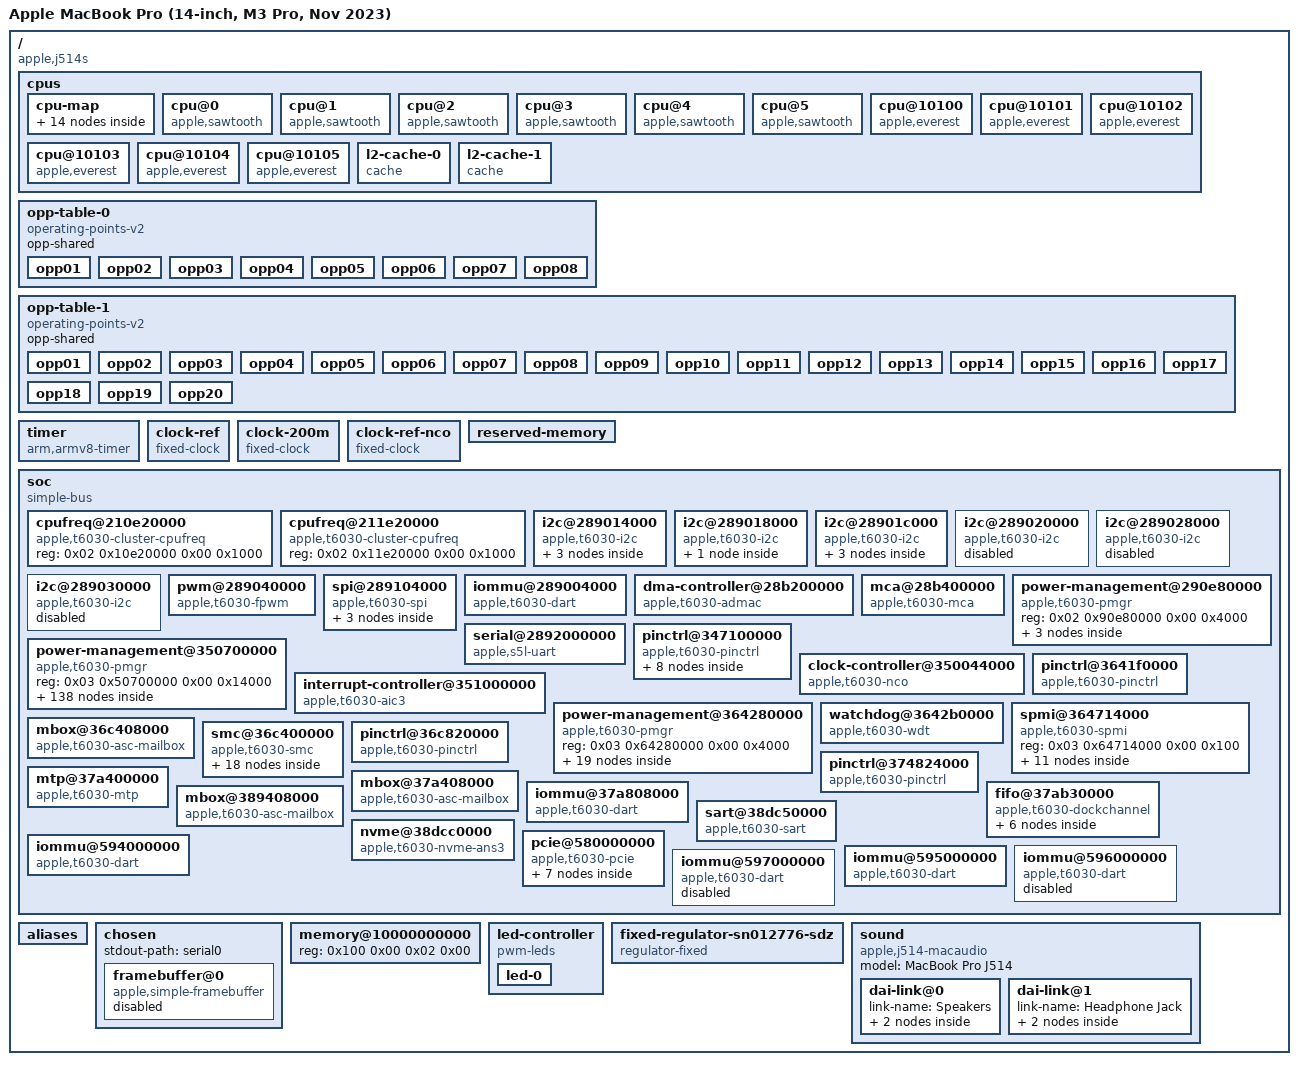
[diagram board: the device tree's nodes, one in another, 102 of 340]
/dts-v1/;

/ {
	#address-cells = <0x02>;
	#size-cells = <0x02>;
	chassis-type = "laptop";
	compatible = "apple,j514s", "apple,t6030", "apple,arm-platform";
	model = "Apple MacBook Pro (14-inch, M3 Pro, Nov 2023)";

	cpus {
		#address-cells = <0x02>;
		#size-cells = <0x00>;

		cpu-map {

			cluster0 {

				core0 {
					cpu = <0x01>;
				};

				core1 {
					cpu = <0x02>;
				};

				core2 {
					cpu = <0x03>;
				};

				core3 {
					cpu = <0x04>;
				};

				core4 {
					cpu = <0x05>;
				};

				core5 {
					cpu = <0x06>;
				};
			};

			cluster1 {

				core0 {
					cpu = <0x07>;
				};

				core1 {
					cpu = <0x08>;
				};

				core2 {
					cpu = <0x09>;
				};

				core3 {
					cpu = <0x0a>;
				};

				core4 {
					cpu = <0x0b>;
				};

				core5 {
					cpu = <0x0c>;
				};
			};
		};

		cpu@0 {
			compatible = "apple,sawtooth";
			device_type = "cpu";
			reg = <0x00 0x00>;
			enable-method = "spin-table";
			cpu-release-addr = <0x00 0x00>;
			next-level-cache = <0x0d>;
			i-cache-size = <0x20000>;
			d-cache-size = <0x10000>;
			operating-points-v2 = <0x0e>;
			capacity-dmips-mhz = <0x353>;
			performance-domains = <0x0f>;
			phandle = <0x01>;
		};

		cpu@1 {
			compatible = "apple,sawtooth";
			device_type = "cpu";
			reg = <0x00 0x01>;
			enable-method = "spin-table";
			cpu-release-addr = <0x00 0x00>;
			next-level-cache = <0x0d>;
			i-cache-size = <0x20000>;
			d-cache-size = <0x10000>;
			operating-points-v2 = <0x0e>;
			capacity-dmips-mhz = <0x353>;
			performance-domains = <0x0f>;
			phandle = <0x02>;
		};

		cpu@2 {
			compatible = "apple,sawtooth";
			device_type = "cpu";
			reg = <0x00 0x02>;
			enable-method = "spin-table";
			cpu-release-addr = <0x00 0x00>;
			next-level-cache = <0x0d>;
			i-cache-size = <0x20000>;
			d-cache-size = <0x10000>;
			operating-points-v2 = <0x0e>;
			capacity-dmips-mhz = <0x353>;
			performance-domains = <0x0f>;
			phandle = <0x03>;
		};

		cpu@3 {
			compatible = "apple,sawtooth";
			device_type = "cpu";
			reg = <0x00 0x03>;
			enable-method = "spin-table";
			cpu-release-addr = <0x00 0x00>;
			next-level-cache = <0x0d>;
			i-cache-size = <0x20000>;
			d-cache-size = <0x10000>;
			operating-points-v2 = <0x0e>;
			capacity-dmips-mhz = <0x353>;
			performance-domains = <0x0f>;
			phandle = <0x04>;
		};

		cpu@4 {
			compatible = "apple,sawtooth";
			device_type = "cpu";
			reg = <0x00 0x04>;
			enable-method = "spin-table";
			cpu-release-addr = <0x00 0x00>;
			next-level-cache = <0x0d>;
			i-cache-size = <0x20000>;
			d-cache-size = <0x10000>;
			operating-points-v2 = <0x0e>;
			capacity-dmips-mhz = <0x353>;
			performance-domains = <0x0f>;
			phandle = <0x05>;
		};

		cpu@5 {
			compatible = "apple,sawtooth";
			device_type = "cpu";
			reg = <0x00 0x05>;
			enable-method = "spin-table";
			cpu-release-addr = <0x00 0x00>;
			next-level-cache = <0x0d>;
			i-cache-size = <0x20000>;
			d-cache-size = <0x10000>;
			operating-points-v2 = <0x0e>;
			capacity-dmips-mhz = <0x353>;
			performance-domains = <0x0f>;
			phandle = <0x06>;
		};

		cpu@10100 {
			compatible = "apple,everest";
			device_type = "cpu";
			reg = <0x00 0x10100>;
			enable-method = "spin-table";
			cpu-release-addr = <0x00 0x00>;
			next-level-cache = <0x10>;
			i-cache-size = <0x30000>;
			d-cache-size = <0x20000>;
			operating-points-v2 = <0x11>;
			capacity-dmips-mhz = <0x400>;
			performance-domains = <0x12>;
			phandle = <0x07>;
		};

		cpu@10101 {
			compatible = "apple,everest";
			device_type = "cpu";
			reg = <0x00 0x10101>;
			enable-method = "spin-table";
			cpu-release-addr = <0x00 0x00>;
			next-level-cache = <0x10>;
			i-cache-size = <0x30000>;
			d-cache-size = <0x20000>;
			operating-points-v2 = <0x11>;
			capacity-dmips-mhz = <0x400>;
			performance-domains = <0x12>;
			phandle = <0x08>;
		};

		cpu@10102 {
			compatible = "apple,everest";
			device_type = "cpu";
			reg = <0x00 0x10102>;
			enable-method = "spin-table";
			cpu-release-addr = <0x00 0x00>;
			next-level-cache = <0x10>;
			i-cache-size = <0x30000>;
			d-cache-size = <0x20000>;
			operating-points-v2 = <0x11>;
			capacity-dmips-mhz = <0x400>;
			performance-domains = <0x12>;
			phandle = <0x09>;
		};

		cpu@10103 {
			compatible = "apple,everest";
			device_type = "cpu";
			reg = <0x00 0x10103>;
			enable-method = "spin-table";
			cpu-release-addr = <0x00 0x00>;
			next-level-cache = <0x10>;
			i-cache-size = <0x30000>;
			d-cache-size = <0x20000>;
			operating-points-v2 = <0x11>;
			capacity-dmips-mhz = <0x400>;
			performance-domains = <0x12>;
			phandle = <0x0a>;
		};

		cpu@10104 {
			compatible = "apple,everest";
			device_type = "cpu";
			reg = <0x00 0x10104>;
			enable-method = "spin-table";
			cpu-release-addr = <0x00 0x00>;
			next-level-cache = <0x10>;
			i-cache-size = <0x30000>;
			d-cache-size = <0x20000>;
			operating-points-v2 = <0x11>;
			capacity-dmips-mhz = <0x400>;
			performance-domains = <0x12>;
			phandle = <0x0b>;
		};

		cpu@10105 {
			compatible = "apple,everest";
			device_type = "cpu";
			reg = <0x00 0x10105>;
			enable-method = "spin-table";
			cpu-release-addr = <0x00 0x00>;
			next-level-cache = <0x10>;
			i-cache-size = <0x30000>;
			d-cache-size = <0x20000>;
			operating-points-v2 = <0x11>;
			capacity-dmips-mhz = <0x400>;
			performance-domains = <0x12>;
			phandle = <0x0c>;
		};

		l2-cache-0 {
			compatible = "cache";
			cache-level = <0x02>;
			cache-unified;
			cache-size = <0x400000>;
			phandle = <0x0d>;
		};

		l2-cache-1 {
			compatible = "cache";
			cache-level = <0x02>;
			cache-unified;
			cache-size = <0x1000000>;
			phandle = <0x10>;
		};
	};

	opp-table-0 {
		compatible = "operating-points-v2";
		opp-shared;
		phandle = <0x0e>;

		opp01 {
			opp-hz = <0x00 0x2c588a00>;
			opp-level = <0x01>;
			clock-latency-ns = <0x1e14>;
		};

		opp02 {
			opp-hz = <0x00 0x3e3a2d00>;
			opp-level = <0x02>;
			clock-latency-ns = <0x52d0>;
		};

		opp03 {
			opp-hz = <0x00 0x57f9f900>;
			opp-level = <0x03>;
			clock-latency-ns = <0x6720>;
		};

		opp04 {
			opp-hz = <0x00 0x77729d00>;
			opp-level = <0x04>;
			clock-latency-ns = <0x9e34>;
		};

		opp05 {
			opp-hz = <0x00 0x872eef00>;
			opp-level = <0x05>;
			clock-latency-ns = <0xad70>;
		};

		opp06 {
			opp-hz = <0x00 0x91e98400>;
			opp-level = <0x06>;
			clock-latency-ns = <0xb860>;
		};

		opp07 {
			opp-hz = <0x00 0x9d5b3400>;
			opp-level = <0x07>;
			clock-latency-ns = <0xcb20>;
		};

		opp08 {
			opp-hz = <0x00 0xa3cb2700>;
			opp-level = <0x08>;
			clock-latency-ns = <0xcb20>;
		};
	};

	opp-table-1 {
		compatible = "operating-points-v2";
		opp-shared;
		phandle = <0x11>;

		opp01 {
			opp-hz = <0x00 0x297c1e00>;
			opp-level = <0x01>;
			clock-latency-ns = <0x2198>;
		};

		opp02 {
			opp-hz = <0x00 0x41169900>;
			opp-level = <0x02>;
			clock-latency-ns = <0x490c>;
		};

		opp03 {
			opp-hz = <0x00 0x50d2eb00>;
			opp-level = <0x03>;
			clock-latency-ns = <0x50dc>;
		};

		opp04 {
			opp-hz = <0x00 0x5f210700>;
			opp-level = <0x04>;
			clock-latency-ns = <0x60e0>;
		};

		opp05 {
			opp-hz = <0x00 0x704b8f00>;
			opp-level = <0x05>;
			clock-latency-ns = <0x77ec>;
		};

		opp06 {
			opp-hz = <0x00 0x81761700>;
			opp-level = <0x06>;
			clock-latency-ns = <0x8660>;
		};

		opp07 {
			opp-hz = <0x00 0x907b4e00>;
			opp-level = <0x07>;
			clock-latency-ns = <0x9ab0>;
		};

		opp08 {
			opp-hz = <0x00 0x9becfe00>;
			opp-level = <0x08>;
			clock-latency-ns = <0x9c40>;
		};

		opp09 {
			opp-hz = <0x00 0xa75eae00>;
			opp-level = <0x09>;
			clock-latency-ns = <0xa348>;
		};

		opp10 {
			opp-hz = <0x00 0xb2194300>;
			opp-level = <0x0a>;
			clock-latency-ns = <0xb0f4>;
		};

		opp11 {
			opp-hz = <0x00 0xbb65a200>;
			opp-level = <0x0b>;
			clock-latency-ns = <0xb66c>;
		};

		opp12 {
			opp-hz = <0x00 0xc3fae600>;
			opp-level = <0x0c>;
			clock-latency-ns = <0xc030>;
		};

		opp13 {
			opp-hz = <0x00 0xcbd90f00>;
			opp-level = <0x0d>;
			clock-latency-ns = <0xd28c>;
		};

		opp14 {
			opp-hz = <0x00 0xd5256e00>;
			opp-level = <0x0e>;
			clock-latency-ns = <0xd1c4>;
		};

		opp15 {
			opp-hz = <0x00 0xd801da00>;
			opp-level = <0x0f>;
			clock-latency-ns = <0xd2f0>;
		};

		opp16 {
			opp-hz = <0x00 0xdd039700>;
			opp-level = <0x10>;
			clock-latency-ns = <0xd2f0>;
		};

		opp17 {
			opp-hz = <0x00 0xe14e3900>;
			opp-level = <0x11>;
			clock-latency-ns = <0xd354>;
		};

		opp18 {
			opp-hz = <0x00 0xe64ff600>;
			opp-level = <0x12>;
			clock-latency-ns = <0xd41c>;
		};

		opp19 {
			opp-hz = <0x00 0xec08ce00>;
			opp-level = <0x13>;
			clock-latency-ns = <0xe420>;
		};

		opp20 {
			opp-hz = <0x00 0xf1c1a600>;
			opp-level = <0x14>;
			clock-latency-ns = <0xe54c>;
		};
	};

	timer {
		compatible = "arm,armv8-timer";
		interrupt-parent = <0x13>;
		interrupt-names = "phys", "virt", "hyp-phys", "hyp-virt";
		interrupts = <0x01 0x02 0x04 0x01 0x03 0x04 0x01 0x00 0x04 0x01 0x01 0x04>;
	};

	clock-ref {
		compatible = "fixed-clock";
		#clock-cells = <0x00>;
		clock-frequency = <0x16e3600>;
		clock-output-names = "clkref";
		phandle = <0x14>;
	};

	clock-200m {
		compatible = "fixed-clock";
		#clock-cells = <0x00>;
		clock-frequency = <0xbebc200>;
		clock-output-names = "clk_200m";
		phandle = <0x25>;
	};

	clock-ref-nco {
		compatible = "fixed-clock";
		#clock-cells = <0x00>;
		clock-output-names = "nco_ref";
		clock-frequency = <0x35a4e900>;
		phandle = <0x58>;
	};

	reserved-memory {
		#address-cells = <0x02>;
		#size-cells = <0x02>;
		ranges;
	};

	soc {
		compatible = "simple-bus";
		#address-cells = <0x02>;
		#size-cells = <0x02>;
		ranges;
		nonposted-mmio;
		dma-ranges = <0x00 0x00 0x00 0x00 0xffffffff 0xffffc000>;

		cpufreq@210e20000 {
			compatible = "apple,t6030-cluster-cpufreq", "apple,t8112-cluster-cpufreq";
			reg = <0x02 0x10e20000 0x00 0x1000>;
			#performance-domain-cells = <0x00>;
			phandle = <0x0f>;
		};

		cpufreq@211e20000 {
			compatible = "apple,t6030-cluster-cpufreq", "apple,t8112-cluster-cpufreq";
			reg = <0x02 0x11e20000 0x00 0x1000>;
			#performance-domain-cells = <0x00>;
			phandle = <0x12>;
		};

		i2c@289014000 {
			compatible = "apple,t6030-i2c", "apple,t8103-i2c";
			reg = <0x02 0x89014000 0x00 0x4000>;
			clocks = <0x14>;
			interrupt-parent = <0x13>;
			interrupts = <0x00 0x37a 0x04>;
			pinctrl-0 = <0x15>;
			pinctrl-names = "default";
			#address-cells = <0x01>;
			#size-cells = <0x00>;
			power-domains = <0x16>;
			status = "okay";

			codec@3a {
				compatible = "ti,sn012776", "ti,tas2764";
				reg = <0x3a>;
				SDZ-supply = <0x17>;
				#sound-dai-cells = <0x00>;
				sound-name-prefix = "Left Tweeter";
				interrupts-extended = <0x18 0x1d 0x08>;
				ti,imon-slot-no = <0x08>;
				ti,vmon-slot-no = <0x0a>;
				phandle = <0x7d>;
			};

			codec@38 {
				compatible = "ti,sn012776", "ti,tas2764";
				reg = <0x38>;
				SDZ-supply = <0x17>;
				#sound-dai-cells = <0x00>;
				sound-name-prefix = "Left Woofer 1";
				interrupts-extended = <0x18 0x1d 0x08>;
				ti,imon-slot-no = <0x00>;
				ti,vmon-slot-no = <0x02>;
				ti,sdout-force-zero-mask = <0xf0f0f0>;
				phandle = <0x7c>;
			};

			codec@39 {
				compatible = "ti,sn012776", "ti,tas2764";
				reg = <0x39>;
				SDZ-supply = <0x17>;
				#sound-dai-cells = <0x00>;
				sound-name-prefix = "Left Woofer 2";
				interrupts-extended = <0x18 0x1d 0x08>;
				ti,imon-slot-no = <0x10>;
				ti,vmon-slot-no = <0x12>;
				phandle = <0x7e>;
			};
		};

		i2c@289018000 {
			compatible = "apple,t6030-i2c", "apple,t8103-i2c";
			reg = <0x02 0x89018000 0x00 0x4000>;
			clocks = <0x14>;
			interrupt-parent = <0x13>;
			interrupts = <0x00 0x37b 0x04>;
			pinctrl-0 = <0x19>;
			pinctrl-names = "default";
			#address-cells = <0x01>;
			#size-cells = <0x00>;
			power-domains = <0x1a>;
			status = "okay";

			codec@4b {
				compatible = "cirrus,cs42l84";
				reg = <0x4b>;
				reset-gpios = <0x1b 0x3a 0x00>;
				#sound-dai-cells = <0x00>;
				interrupts-extended = <0x18 0x1e 0x08>;
				sound-name-prefix = "Jack";
				phandle = <0x82>;
			};
		};

		i2c@28901c000 {
			compatible = "apple,t6030-i2c", "apple,t8103-i2c";
			reg = <0x02 0x8901c000 0x00 0x4000>;
			clocks = <0x14>;
			interrupt-parent = <0x13>;
			interrupts = <0x00 0x37c 0x04>;
			pinctrl-0 = <0x1c>;
			pinctrl-names = "default";
			#address-cells = <0x01>;
			#size-cells = <0x00>;
			power-domains = <0x1d>;
			status = "okay";

			codec@3d {
				compatible = "ti,sn012776", "ti,tas2764";
				reg = <0x3d>;
				SDZ-supply = <0x17>;
				#sound-dai-cells = <0x00>;
				sound-name-prefix = "Right Tweeter";
				interrupts-extended = <0x18 0x1d 0x08>;
				ti,imon-slot-no = <0x0c>;
				ti,vmon-slot-no = <0x0e>;
				phandle = <0x80>;
			};

			codec@3b {
				compatible = "ti,sn012776", "ti,tas2764";
				reg = <0x3b>;
				SDZ-supply = <0x17>;
				#sound-dai-cells = <0x00>;
				sound-name-prefix = "Right Woofer 1";
				interrupts-extended = <0x18 0x1d 0x08>;
				ti,imon-slot-no = <0x04>;
				ti,vmon-slot-no = <0x06>;
				ti,sdout-force-zero-mask = <0xf0f0f>;
				phandle = <0x7f>;
			};

			codec@3c {
				compatible = "ti,sn012776", "ti,tas2764";
				reg = <0x3c>;
				SDZ-supply = <0x17>;
				#sound-dai-cells = <0x00>;
				sound-name-prefix = "Right Woofer 2";
				interrupts-extended = <0x18 0x1d 0x08>;
				ti,imon-slot-no = <0x14>;
				ti,vmon-slot-no = <0x16>;
				phandle = <0x81>;
			};
		};

		i2c@289020000 {
			compatible = "apple,t6030-i2c", "apple,t8103-i2c";
			reg = <0x02 0x89020000 0x00 0x4000>;
			clocks = <0x14>;
			interrupt-parent = <0x13>;
			interrupts = <0x00 0x37d 0x04>;
			pinctrl-0 = <0x1e>;
			pinctrl-names = "default";
			#address-cells = <0x01>;
			#size-cells = <0x00>;
			power-domains = <0x1f>;
			status = "disabled";
		};

		i2c@289028000 {
			compatible = "apple,t6030-i2c", "apple,t8103-i2c";
			reg = <0x02 0x89028000 0x00 0x4000>;
			clocks = <0x14>;
			interrupt-parent = <0x13>;
			interrupts = <0x00 0x37f 0x04>;
			pinctrl-0 = <0x20>;
			pinctrl-names = "default";
			#address-cells = <0x01>;
			#size-cells = <0x00>;
			power-domains = <0x21>;
			status = "disabled";
		};

		i2c@289030000 {
			compatible = "apple,t6030-i2c", "apple,t8103-i2c";
			reg = <0x02 0x89030000 0x00 0x4000>;
			clocks = <0x14>;
			interrupt-parent = <0x13>;
			interrupts = <0x00 0x381 0x04>;
			pinctrl-0 = <0x22>;
			pinctrl-names = "default";
			#address-cells = <0x01>;
			#size-cells = <0x00>;
			power-domains = <0x23>;
			status = "disabled";
		};

		pwm@289040000 {
			compatible = "apple,t6030-fpwm", "apple,s5l-fpwm";
			reg = <0x02 0x89040000 0x00 0x4000>;
			power-domains = <0x24>;
			clocks = <0x14>;
			#pwm-cells = <0x02>;
			status = "okay";
			phandle = <0x7a>;
		};

		spi@289104000 {
			compatible = "apple,t6030-spi", "apple,t8103-spi";
			reg = <0x02 0x89104000 0x00 0x4000>;
			interrupt-parent = <0x13>;
			interrupts = <0x00 0x36b 0x04>;
			#address-cells = <0x01>;
			#size-cells = <0x00>;
			clocks = <0x25>;
			pinctrl-0 = <0x26>;
			pinctrl-names = "default";
			power-domains = <0x27>;
			status = "okay";

			flash@0 {
				compatible = "jedec,spi-nor";
				reg = <0x00>;
				spi-max-frequency = <0x17d7840>;

				partitions {
					compatible = "fixed-partitions";
					#address-cells = <0x01>;
					#size-cells = <0x01>;

					partition@700000 {
						label = "nvram";
						reg = <0x00 0x00>;
						status = "disabled";
					};
				};
			};
		};

		iommu@289004000 {
			compatible = "apple,t6030-dart", "apple,t8110-dart";
			reg = <0x02 0x89004000 0x00 0x4000>;
			interrupt-parent = <0x13>;
			interrupts = <0x00 0x385 0x04>;
			#iommu-cells = <0x01>;
			power-domains = <0x28>;
			phandle = <0x29>;
		};

		dma-controller@28b200000 {
			compatible = "apple,t6030-admac", "apple,t8103-admac";
			reg = <0x02 0x8b200000 0x00 0x34000>;
			#dma-cells = <0x01>;
			dma-channels = <0x18>;
			interrupts-extended = <0x00 0x13 0x00 0x378 0x04 0x00 0x00>;
			iommus = <0x29 0x02>;
			power-domains = <0x2a>;
			resets = <0x2b>;
			phandle = <0x2d>;
		};

		mca@28b400000 {
			compatible = "apple,t6030-mca", "apple,t8103-mca";
			reg = <0x02 0x8b400000 0x00 0x10000 0x02 0x8b300000 0x00 0x20000>;
			clocks = <0x2c 0x00 0x2c 0x01 0x2c 0x02 0x2c 0x03>;
			dmas = <0x2d 0x00 0x2d 0x01 0x2d 0x02 0x2d 0x03 0x2d 0x04 0x2d 0x05 0x2d 0x06 0x2d 0x07 0x2d 0x08 0x2d 0x09 0x2d 0x0a 0x2d 0x0b 0x2d 0x0c 0x2d 0x0d 0x2d 0x0e 0x2d 0x0f>;
			dma-names = "tx0a", "rx0a", "tx0b", "rx0b", "tx1a", "rx1a", "tx1b", "rx1b", "tx2a", "rx2a", "tx2b", "rx2b", "tx3a", "rx3a", "tx3b", "rx3b";
			interrupt-parent = <0x13>;
			interrupts = <0x00 0x371 0x04 0x00 0x372 0x04 0x00 0x373 0x04 0x00 0x374 0x04>;
			power-domains = <0x2b 0x2e 0x2f 0x30 0x31>;
			resets = <0x2b>;
			#sound-dai-cells = <0x01>;
			phandle = <0x7b>;
		};

		power-management@290e80000 {
			compatible = "apple,t6030-pmgr", "apple,t8103-pmgr", "syscon", "simple-mfd";
			#address-cells = <0x01>;
			#size-cells = <0x01>;
			reg = <0x02 0x90e80000 0x00 0x4000>;

			power-controller@0 {
				compatible = "apple,t6030-pmgr-pwrstate", "apple,t8103-pmgr-pwrstate";
				reg = <0x00 0x04>;
				#power-domain-cells = <0x00>;
				#reset-cells = <0x00>;
				label = "gpx";
				apple,always-on;
				phandle = <0x32>;
			};

			power-controller@100 {
				compatible = "apple,t6030-pmgr-pwrstate", "apple,t8103-pmgr-pwrstate";
				reg = <0x100 0x04>;
				#power-domain-cells = <0x00>;
				#reset-cells = <0x00>;
				label = "afr";
				apple,always-on;
				phandle = <0x33>;
			};

			power-controller@110 {
				compatible = "apple,t6030-pmgr-pwrstate", "apple,t8103-pmgr-pwrstate";
				reg = <0x110 0x04>;
				#power-domain-cells = <0x00>;
				#reset-cells = <0x00>;
				label = "gfx";
				power-domains = <0x32 0x33>;
			};
		};

		serial@2892000000 {
			compatible = "apple,s5l-uart";
			reg = <0x02 0x89200000 0x00 0x1000>;
			reg-io-width = <0x04>;
			interrupt-parent = <0x13>;
			interrupts = <0x00 0x362 0x04>;
			clocks = <0x14 0x14>;
			clock-names = "uart", "clk_uart_baud0";
			power-domains = <0x34>;
			status = "okay";
		};

		pinctrl@347100000 {
			compatible = "apple,t6030-pinctrl", "apple,t8103-pinctrl";
			reg = <0x03 0x47100000 0x00 0x4000>;
			interrupt-parent = <0x13>;
			interrupts = <0x00 0x111 0x04 0x00 0x112 0x04 0x00 0x113 0x04 0x00 0x114 0x04 0x00 0x115 0x04 0x00 0x116 0x04 0x00 0x117 0x04>;
			power-domains = <0x35>;
			gpio-controller;
			#gpio-cells = <0x02>;
			gpio-ranges = <0x18 0x00 0x00 0xe0>;
			apple,npins = <0xe0>;
			interrupt-controller;
			#interrupt-cells = <0x02>;
			phandle = <0x18>;

			i2c1-pins {
				pinmux = <0x10025 0x10024>;
				phandle = <0x15>;
			};

			i2c2-pins {
				pinmux = <0x1002b 0x1002a>;
				phandle = <0x19>;
			};

			i2c3-pins {
				pinmux = <0x10029 0x10028>;
				phandle = <0x1c>;
			};

			i2c4-pins {
				pinmux = <0x10027 0x10026>;
				phandle = <0x1e>;
			};

			i2c6-pins {
				pinmux = <0x1002f 0x1002e>;
				phandle = <0x20>;
			};

			i2c8-pins {
				pinmux = <0x10033 0x10032>;
				phandle = <0x22>;
			};

			spi1-pins {
				pinmux = <0x10018 0x10019 0x1001a 0x1001b>;
				phandle = <0x26>;
			};

			pcie-pins {
				pinmux = <0x100a3 0x100a4 0x100a5 0x100a6>;
				phandle = <0x73>;
			};
		};

		power-management@350700000 {
			compatible = "apple,t6030-pmgr", "apple,t8103-pmgr", "syscon", "simple-mfd";
			#address-cells = <0x01>;
			#size-cells = <0x01>;
			reg = <0x03 0x50700000 0x00 0x14000>;

			power-controller@108 {
				compatible = "apple,t6030-pmgr-pwrstate", "apple,t8103-pmgr-pwrstate";
				reg = <0x108 0x04>;
				#power-domain-cells = <0x00>;
				#reset-cells = <0x00>;
				label = "msg";
				apple,always-on;
			};

			power-controller@110 {
				compatible = "apple,t6030-pmgr-pwrstate", "apple,t8103-pmgr-pwrstate";
				reg = <0x110 0x04>;
				#power-domain-cells = <0x00>;
				#reset-cells = <0x00>;
				label = "aic";
				phandle = <0x59>;
			};

			power-controller@118 {
				compatible = "apple,t6030-pmgr-pwrstate", "apple,t8103-pmgr-pwrstate";
				reg = <0x118 0x04>;
				#power-domain-cells = <0x00>;
				#reset-cells = <0x00>;
				label = "dwi";
			};

			power-controller@120 {
				compatible = "apple,t6030-pmgr-pwrstate", "apple,t8103-pmgr-pwrstate";
				reg = <0x120 0x04>;
				#power-domain-cells = <0x00>;
				#reset-cells = <0x00>;
				label = "gpio";
				phandle = <0x35>;
			};

			power-controller@138 {
				compatible = "apple,t6030-pmgr-pwrstate", "apple,t8103-pmgr-pwrstate";
				reg = <0x138 0x04>;
				#power-domain-cells = <0x00>;
				#reset-cells = <0x00>;
				label = "pms_fpwm0";
			};

			power-controller@140 {
				compatible = "apple,t6030-pmgr-pwrstate", "apple,t8103-pmgr-pwrstate";
				reg = <0x140 0x04>;
				#power-domain-cells = <0x00>;
				#reset-cells = <0x00>;
				label = "pms_fpwm1";
			};

			power-controller@148 {
				compatible = "apple,t6030-pmgr-pwrstate", "apple,t8103-pmgr-pwrstate";
				reg = <0x148 0x04>;
				#power-domain-cells = <0x00>;
				#reset-cells = <0x00>;
				label = "pms_fpwm2";
			};

			power-controller@150 {
				compatible = "apple,t6030-pmgr-pwrstate", "apple,t8103-pmgr-pwrstate";
				reg = <0x150 0x04>;
				#power-domain-cells = <0x00>;
				#reset-cells = <0x00>;
				label = "pms_fpwm3";
			};

			power-controller@158 {
				compatible = "apple,t6030-pmgr-pwrstate", "apple,t8103-pmgr-pwrstate";
				reg = <0x158 0x04>;
				#power-domain-cells = <0x00>;
				#reset-cells = <0x00>;
				label = "pms_fpwm4";
			};

			power-controller@160 {
				compatible = "apple,t6030-pmgr-pwrstate", "apple,t8103-pmgr-pwrstate";
				reg = <0x160 0x04>;
				#power-domain-cells = <0x00>;
				#reset-cells = <0x00>;
				label = "pms_c1ppt";
			};

			power-controller@168 {
				compatible = "apple,t6030-pmgr-pwrstate", "apple,t8103-pmgr-pwrstate";
				reg = <0x168 0x04>;
				#power-domain-cells = <0x00>;
				#reset-cells = <0x00>;
				label = "soc_rc";
			};

			power-controller@170 {
				compatible = "apple,t6030-pmgr-pwrstate", "apple,t8103-pmgr-pwrstate";
				reg = <0x170 0x04>;
				#power-domain-cells = <0x00>;
				#reset-cells = <0x00>;
				label = "soc_dpe";
				apple,always-on;
			};

			power-controller@178 {
				compatible = "apple,t6030-pmgr-pwrstate", "apple,t8103-pmgr-pwrstate";
				reg = <0x178 0x04>;
				#power-domain-cells = <0x00>;
				#reset-cells = <0x00>;
				label = "pmgr_soc_ocla";
			};

			power-controller@180 {
				compatible = "apple,t6030-pmgr-pwrstate", "apple,t8103-pmgr-pwrstate";
				reg = <0x180 0x04>;
				#power-domain-cells = <0x00>;
				#reset-cells = <0x00>;
				label = "ispsens0";
			};

			power-controller@190 {
				compatible = "apple,t6030-pmgr-pwrstate", "apple,t8103-pmgr-pwrstate";
				reg = <0x190 0x04>;
				#power-domain-cells = <0x00>;
				#reset-cells = <0x00>;
				label = "aft0";
			};

			power-controller@1a8 {
				compatible = "apple,t6030-pmgr-pwrstate", "apple,t8103-pmgr-pwrstate";
				reg = <0x1a8 0x04>;
				#power-domain-cells = <0x00>;
				#reset-cells = <0x00>;
				label = "ap_tmm";
			};

			power-controller@1b8 {
				compatible = "apple,t6030-pmgr-pwrstate", "apple,t8103-pmgr-pwrstate";
				reg = <0x1b8 0x04>;
				#power-domain-cells = <0x00>;
				#reset-cells = <0x00>;
				label = "sio";
				phandle = <0x28>;
			};

			power-controller@1c0 {
				compatible = "apple,t6030-pmgr-pwrstate", "apple,t8103-pmgr-pwrstate";
				reg = <0x1c0 0x04>;
				#power-domain-cells = <0x00>;
				#reset-cells = <0x00>;
				label = "disp_sys";
				phandle = <0x36>;
			};

			power-controller@1c8 {
				compatible = "apple,t6030-pmgr-pwrstate", "apple,t8103-pmgr-pwrstate";
				reg = <0x1c8 0x04>;
				#power-domain-cells = <0x00>;
				#reset-cells = <0x00>;
				label = "jpg";
			};

			power-controller@1d0 {
				compatible = "apple,t6030-pmgr-pwrstate", "apple,t8103-pmgr-pwrstate";
				reg = <0x1d0 0x04>;
				#power-domain-cells = <0x00>;
				#reset-cells = <0x00>;
				label = "sio_cpu";
				power-domains = <0x28>;
			};

			power-controller@1d8 {
				compatible = "apple,t6030-pmgr-pwrstate", "apple,t8103-pmgr-pwrstate";
				reg = <0x1d8 0x04>;
				#power-domain-cells = <0x00>;
				#reset-cells = <0x00>;
				label = "fpwm0";
				power-domains = <0x28>;
				phandle = <0x24>;
			};

			power-controller@1e0 {
				compatible = "apple,t6030-pmgr-pwrstate", "apple,t8103-pmgr-pwrstate";
				reg = <0x1e0 0x04>;
				#power-domain-cells = <0x00>;
				#reset-cells = <0x00>;
				label = "fpwm1";
				power-domains = <0x28>;
			};

			power-controller@1e8 {
				compatible = "apple,t6030-pmgr-pwrstate", "apple,t8103-pmgr-pwrstate";
				reg = <0x1e8 0x04>;
				#power-domain-cells = <0x00>;
				#reset-cells = <0x00>;
				label = "fpwm2";
				power-domains = <0x28>;
			};

			power-controller@1f0 {
				compatible = "apple,t6030-pmgr-pwrstate", "apple,t8103-pmgr-pwrstate";
				reg = <0x1f0 0x04>;
				#power-domain-cells = <0x00>;
				#reset-cells = <0x00>;
				label = "i2c0";
				power-domains = <0x28>;
			};

			power-controller@1f8 {
				compatible = "apple,t6030-pmgr-pwrstate", "apple,t8103-pmgr-pwrstate";
				reg = <0x1f8 0x04>;
				#power-domain-cells = <0x00>;
				#reset-cells = <0x00>;
				label = "i2c1";
				power-domains = <0x28>;
				phandle = <0x16>;
			};

			power-controller@200 {
				compatible = "apple,t6030-pmgr-pwrstate", "apple,t8103-pmgr-pwrstate";
				reg = <0x200 0x04>;
				#power-domain-cells = <0x00>;
				#reset-cells = <0x00>;
				label = "i2c2";
				power-domains = <0x28>;
				phandle = <0x1a>;
			};

			power-controller@208 {
				compatible = "apple,t6030-pmgr-pwrstate", "apple,t8103-pmgr-pwrstate";
				reg = <0x208 0x04>;
				#power-domain-cells = <0x00>;
				#reset-cells = <0x00>;
				label = "i2c3";
				power-domains = <0x28>;
				phandle = <0x1d>;
			};

			power-controller@210 {
				compatible = "apple,t6030-pmgr-pwrstate", "apple,t8103-pmgr-pwrstate";
				reg = <0x210 0x04>;
				#power-domain-cells = <0x00>;
				#reset-cells = <0x00>;
				label = "i2c4";
				power-domains = <0x28>;
				phandle = <0x1f>;
			};

			power-controller@218 {
				compatible = "apple,t6030-pmgr-pwrstate", "apple,t8103-pmgr-pwrstate";
				reg = <0x218 0x04>;
				#power-domain-cells = <0x00>;
				#reset-cells = <0x00>;
				label = "i2c5";
				power-domains = <0x28>;
			};

			power-controller@220 {
				compatible = "apple,t6030-pmgr-pwrstate", "apple,t8103-pmgr-pwrstate";
				reg = <0x220 0x04>;
				#power-domain-cells = <0x00>;
				#reset-cells = <0x00>;
				label = "i2c6";
				power-domains = <0x28>;
				phandle = <0x21>;
			};

			power-controller@228 {
				compatible = "apple,t6030-pmgr-pwrstate", "apple,t8103-pmgr-pwrstate";
				reg = <0x228 0x04>;
				#power-domain-cells = <0x00>;
				#reset-cells = <0x00>;
				label = "i2c7";
				power-domains = <0x28>;
			};

			power-controller@230 {
				compatible = "apple,t6030-pmgr-pwrstate", "apple,t8103-pmgr-pwrstate";
				reg = <0x230 0x04>;
				#power-domain-cells = <0x00>;
				#reset-cells = <0x00>;
				label = "i2c8";
				power-domains = <0x28>;
				phandle = <0x23>;
			};

			power-controller@238 {
				compatible = "apple,t6030-pmgr-pwrstate", "apple,t8103-pmgr-pwrstate";
				reg = <0x238 0x04>;
				#power-domain-cells = <0x00>;
				#reset-cells = <0x00>;
				label = "spi_p";
				power-domains = <0x28>;
				phandle = <0x37>;
			};

			power-controller@240 {
				compatible = "apple,t6030-pmgr-pwrstate", "apple,t8103-pmgr-pwrstate";
				reg = <0x240 0x04>;
				#power-domain-cells = <0x00>;
				#reset-cells = <0x00>;
				label = "uart_p";
				power-domains = <0x28>;
				phandle = <0x38>;
			};

			power-controller@248 {
				compatible = "apple,t6030-pmgr-pwrstate", "apple,t8103-pmgr-pwrstate";
				reg = <0x248 0x04>;
				#power-domain-cells = <0x00>;
				#reset-cells = <0x00>;
				label = "audio_p";
				power-domains = <0x28>;
				phandle = <0x2b>;
			};

			power-controller@250 {
				compatible = "apple,t6030-pmgr-pwrstate", "apple,t8103-pmgr-pwrstate";
				reg = <0x250 0x04>;
				#power-domain-cells = <0x00>;
				#reset-cells = <0x00>;
				label = "aes";
				power-domains = <0x28>;
			};

			power-controller@258 {
				compatible = "apple,t6030-pmgr-pwrstate", "apple,t8103-pmgr-pwrstate";
				reg = <0x258 0x04>;
				#power-domain-cells = <0x00>;
				#reset-cells = <0x00>;
				label = "disp_fe";
				power-domains = <0x36>;
				phandle = <0x57>;
			};

			power-controller@260 {
				compatible = "apple,t6030-pmgr-pwrstate", "apple,t8103-pmgr-pwrstate";
				reg = <0x260 0x04>;
				#power-domain-cells = <0x00>;
				#reset-cells = <0x00>;
				label = "spi0";
				power-domains = <0x37>;
			};

			power-controller@268 {
				compatible = "apple,t6030-pmgr-pwrstate", "apple,t8103-pmgr-pwrstate";
				reg = <0x268 0x04>;
				#power-domain-cells = <0x00>;
				#reset-cells = <0x00>;
				label = "spi1";
				power-domains = <0x37>;
				phandle = <0x27>;
			};

			power-controller@270 {
				compatible = "apple,t6030-pmgr-pwrstate", "apple,t8103-pmgr-pwrstate";
				reg = <0x270 0x04>;
				#power-domain-cells = <0x00>;
				#reset-cells = <0x00>;
				label = "spi2";
				power-domains = <0x37>;
			};

			power-controller@278 {
				compatible = "apple,t6030-pmgr-pwrstate", "apple,t8103-pmgr-pwrstate";
				reg = <0x278 0x04>;
				#power-domain-cells = <0x00>;
				#reset-cells = <0x00>;
				label = "spi3";
				power-domains = <0x37>;
			};

			power-controller@280 {
				compatible = "apple,t6030-pmgr-pwrstate", "apple,t8103-pmgr-pwrstate";
				reg = <0x280 0x04>;
				#power-domain-cells = <0x00>;
				#reset-cells = <0x00>;
				label = "spi4";
				power-domains = <0x37>;
			};

			power-controller@288 {
				compatible = "apple,t6030-pmgr-pwrstate", "apple,t8103-pmgr-pwrstate";
				reg = <0x288 0x04>;
				#power-domain-cells = <0x00>;
				#reset-cells = <0x00>;
				label = "spi5";
				power-domains = <0x37>;
			};

			power-controller@290 {
				compatible = "apple,t6030-pmgr-pwrstate", "apple,t8103-pmgr-pwrstate";
				reg = <0x290 0x04>;
				#power-domain-cells = <0x00>;
				#reset-cells = <0x00>;
				label = "qspi";
				power-domains = <0x37>;
			};

			power-controller@298 {
				compatible = "apple,t6030-pmgr-pwrstate", "apple,t8103-pmgr-pwrstate";
				reg = <0x298 0x04>;
				#power-domain-cells = <0x00>;
				#reset-cells = <0x00>;
				label = "uart_n";
				power-domains = <0x38>;
			};

			power-controller@2a0 {
				compatible = "apple,t6030-pmgr-pwrstate", "apple,t8103-pmgr-pwrstate";
				reg = <0x2a0 0x04>;
				#power-domain-cells = <0x00>;
				#reset-cells = <0x00>;
				label = "uart0";
				power-domains = <0x38>;
				phandle = <0x34>;
			};

			power-controller@2a8 {
				compatible = "apple,t6030-pmgr-pwrstate", "apple,t8103-pmgr-pwrstate";
				reg = <0x2a8 0x04>;
				#power-domain-cells = <0x00>;
				#reset-cells = <0x00>;
				label = "uart1";
				power-domains = <0x38>;
			};

			power-controller@2b0 {
				compatible = "apple,t6030-pmgr-pwrstate", "apple,t8103-pmgr-pwrstate";
				reg = <0x2b0 0x04>;
				#power-domain-cells = <0x00>;
				#reset-cells = <0x00>;
				label = "uart2";
				power-domains = <0x38>;
			};

			power-controller@2b8 {
				compatible = "apple,t6030-pmgr-pwrstate", "apple,t8103-pmgr-pwrstate";
				reg = <0x2b8 0x04>;
				#power-domain-cells = <0x00>;
				#reset-cells = <0x00>;
				label = "uart3";
				power-domains = <0x38>;
			};

			power-controller@2c0 {
				compatible = "apple,t6030-pmgr-pwrstate", "apple,t8103-pmgr-pwrstate";
				reg = <0x2c0 0x04>;
				#power-domain-cells = <0x00>;
				#reset-cells = <0x00>;
				label = "uart4";
				power-domains = <0x38>;
			};

			power-controller@2c8 {
				compatible = "apple,t6030-pmgr-pwrstate", "apple,t8103-pmgr-pwrstate";
				reg = <0x2c8 0x04>;
				#power-domain-cells = <0x00>;
				#reset-cells = <0x00>;
				label = "uart5";
				power-domains = <0x38>;
			};

			power-controller@2d0 {
				compatible = "apple,t6030-pmgr-pwrstate", "apple,t8103-pmgr-pwrstate";
				reg = <0x2d0 0x04>;
				#power-domain-cells = <0x00>;
				#reset-cells = <0x00>;
				label = "uart6";
				power-domains = <0x38>;
			};

			power-controller@2d8 {
				compatible = "apple,t6030-pmgr-pwrstate", "apple,t8103-pmgr-pwrstate";
				reg = <0x2d8 0x04>;
				#power-domain-cells = <0x00>;
				#reset-cells = <0x00>;
				label = "sio_adma";
				power-domains = <0x2b>;
				phandle = <0x2a>;
			};

			power-controller@2e0 {
				compatible = "apple,t6030-pmgr-pwrstate", "apple,t8103-pmgr-pwrstate";
				reg = <0x2e0 0x04>;
				#power-domain-cells = <0x00>;
				#reset-cells = <0x00>;
				label = "dpa0";
				apple,always-on;
				power-domains = <0x2b>;
			};

			power-controller@2e8 {
				compatible = "apple,t6030-pmgr-pwrstate", "apple,t8103-pmgr-pwrstate";
				reg = <0x2e8 0x04>;
				#power-domain-cells = <0x00>;
				#reset-cells = <0x00>;
				label = "dpa1";
				apple,always-on;
				power-domains = <0x2b>;
			};

			power-controller@2f0 {
				compatible = "apple,t6030-pmgr-pwrstate", "apple,t8103-pmgr-pwrstate";
				reg = <0x2f0 0x04>;
				#power-domain-cells = <0x00>;
				#reset-cells = <0x00>;
				label = "dpa2";
				apple,always-on;
				power-domains = <0x2b>;
			};

			power-controller@2f8 {
				compatible = "apple,t6030-pmgr-pwrstate", "apple,t8103-pmgr-pwrstate";
				reg = <0x2f8 0x04>;
				#power-domain-cells = <0x00>;
				#reset-cells = <0x00>;
				label = "dpa3";
				apple,always-on;
				power-domains = <0x2b>;
			};

			power-controller@300 {
				compatible = "apple,t6030-pmgr-pwrstate", "apple,t8103-pmgr-pwrstate";
				reg = <0x300 0x04>;
				#power-domain-cells = <0x00>;
				#reset-cells = <0x00>;
				label = "dpa4";
				apple,always-on;
				power-domains = <0x2b>;
			};

			power-controller@308 {
				compatible = "apple,t6030-pmgr-pwrstate", "apple,t8103-pmgr-pwrstate";
				reg = <0x308 0x04>;
				#power-domain-cells = <0x00>;
				#reset-cells = <0x00>;
				label = "mca0";
				power-domains = <0x2a 0x2b>;
				apple,externally-clocked;
				phandle = <0x2e>;
			};

			power-controller@320 {
				compatible = "apple,t6030-pmgr-pwrstate", "apple,t8103-pmgr-pwrstate";
				reg = <0x320 0x04>;
				#power-domain-cells = <0x00>;
				#reset-cells = <0x00>;
				label = "dcs0";
				apple,always-on;
			};

			power-controller@328 {
				compatible = "apple,t6030-pmgr-pwrstate", "apple,t8103-pmgr-pwrstate";
				reg = <0x328 0x04>;
				#power-domain-cells = <0x00>;
				#reset-cells = <0x00>;
				label = "dcs2";
				apple,always-on;
			};

			power-controller@330 {
				compatible = "apple,t6030-pmgr-pwrstate", "apple,t8103-pmgr-pwrstate";
				reg = <0x330 0x04>;
				#power-domain-cells = <0x00>;
				#reset-cells = <0x00>;
				label = "dcs1";
				apple,always-on;
			};

			power-controller@338 {
				compatible = "apple,t6030-pmgr-pwrstate", "apple,t8103-pmgr-pwrstate";
				reg = <0x338 0x04>;
				#power-domain-cells = <0x00>;
				#reset-cells = <0x00>;
				label = "dcs3";
				apple,always-on;
			};

			power-controller@340 {
				compatible = "apple,t6030-pmgr-pwrstate", "apple,t8103-pmgr-pwrstate";
				reg = <0x340 0x04>;
				#power-domain-cells = <0x00>;
				#reset-cells = <0x00>;
				label = "dcs4";
				apple,always-on;
			};

			power-controller@348 {
				compatible = "apple,t6030-pmgr-pwrstate", "apple,t8103-pmgr-pwrstate";
				reg = <0x348 0x04>;
				#power-domain-cells = <0x00>;
				#reset-cells = <0x00>;
				label = "dcs5";
				apple,always-on;
			};

			power-controller@358 {
				compatible = "apple,t6030-pmgr-pwrstate", "apple,t8103-pmgr-pwrstate";
				reg = <0x358 0x04>;
				#power-domain-cells = <0x00>;
				#reset-cells = <0x00>;
				label = "dcs6";
				apple,always-on;
			};

			power-controller@360 {
				compatible = "apple,t6030-pmgr-pwrstate", "apple,t8103-pmgr-pwrstate";
				reg = <0x360 0x04>;
				#power-domain-cells = <0x00>;
				#reset-cells = <0x00>;
				label = "dcs7";
				apple,always-on;
			};

			power-controller@368 {
				compatible = "apple,t6030-pmgr-pwrstate", "apple,t8103-pmgr-pwrstate";
				reg = <0x368 0x04>;
				#power-domain-cells = <0x00>;
				#reset-cells = <0x00>;
				label = "dcs8";
				apple,always-on;
			};

			power-controller@370 {
				compatible = "apple,t6030-pmgr-pwrstate", "apple,t8103-pmgr-pwrstate";
				reg = <0x370 0x04>;
				#power-domain-cells = <0x00>;
				#reset-cells = <0x00>;
				label = "dcs9";
				apple,always-on;
			};

			power-controller@378 {
				compatible = "apple,t6030-pmgr-pwrstate", "apple,t8103-pmgr-pwrstate";
				reg = <0x378 0x04>;
				#power-domain-cells = <0x00>;
				#reset-cells = <0x00>;
				label = "dcs10";
				apple,always-on;
			};

			power-controller@380 {
				compatible = "apple,t6030-pmgr-pwrstate", "apple,t8103-pmgr-pwrstate";
				reg = <0x380 0x04>;
				#power-domain-cells = <0x00>;
				#reset-cells = <0x00>;
				label = "dcs11";
				apple,always-on;
			};

			power-controller@388 {
				compatible = "apple,t6030-pmgr-pwrstate", "apple,t8103-pmgr-pwrstate";
				reg = <0x388 0x04>;
				#power-domain-cells = <0x00>;
				#reset-cells = <0x00>;
				label = "mca1";
				power-domains = <0x2a 0x2b>;
				apple,externally-clocked;
				phandle = <0x2f>;
			};

			power-controller@390 {
				compatible = "apple,t6030-pmgr-pwrstate", "apple,t8103-pmgr-pwrstate";
				reg = <0x390 0x04>;
				#power-domain-cells = <0x00>;
				#reset-cells = <0x00>;
				label = "mca2";
				power-domains = <0x2a 0x2b>;
				apple,externally-clocked;
				phandle = <0x30>;
			};

			power-controller@398 {
				compatible = "apple,t6030-pmgr-pwrstate", "apple,t8103-pmgr-pwrstate";
				reg = <0x398 0x04>;
				#power-domain-cells = <0x00>;
				#reset-cells = <0x00>;
				label = "mca3";
				power-domains = <0x2a 0x2b>;
				apple,externally-clocked;
				phandle = <0x31>;
			};

			power-controller@3a0 {
				compatible = "apple,t6030-pmgr-pwrstate", "apple,t8103-pmgr-pwrstate";
				reg = <0x3a0 0x04>;
				#power-domain-cells = <0x00>;
				#reset-cells = <0x00>;
				label = "ioa1";
				apple,always-on;
				phandle = <0x39>;
			};

			power-controller@3a8 {
				compatible = "apple,t6030-pmgr-pwrstate", "apple,t8103-pmgr-pwrstate";
				reg = <0x3a8 0x04>;
				#power-domain-cells = <0x00>;
				#reset-cells = <0x00>;
				label = "ls1";
				apple,always-on;
				power-domains = <0x39>;
				phandle = <0x3a>;
			};

			power-controller@3b0 {
				compatible = "apple,t6030-pmgr-pwrstate", "apple,t8103-pmgr-pwrstate";
				reg = <0x3b0 0x04>;
				#power-domain-cells = <0x00>;
				#reset-cells = <0x00>;
				label = "lw10";
				apple,always-on;
				power-domains = <0x3a>;
				phandle = <0x3b>;
			};

			power-controller@3b8 {
				compatible = "apple,t6030-pmgr-pwrstate", "apple,t8103-pmgr-pwrstate";
				reg = <0x3b8 0x04>;
				#power-domain-cells = <0x00>;
				#reset-cells = <0x00>;
				label = "dispext0_sys";
				power-domains = <0x3b>;
				phandle = <0x3c>;
			};

			power-controller@3c0 {
				compatible = "apple,t6030-pmgr-pwrstate", "apple,t8103-pmgr-pwrstate";
				reg = <0x3c0 0x04>;
				#power-domain-cells = <0x00>;
				#reset-cells = <0x00>;
				label = "dispext1_sys";
				power-domains = <0x3b>;
				phandle = <0x3e>;
			};

			power-controller@3c8 {
				compatible = "apple,t6030-pmgr-pwrstate", "apple,t8103-pmgr-pwrstate";
				reg = <0x3c8 0x04>;
				#power-domain-cells = <0x00>;
				#reset-cells = <0x00>;
				label = "isp_sys";
				power-domains = <0x3b>;
				phandle = <0x51>;
			};

			power-controller@3d0 {
				compatible = "apple,t6030-pmgr-pwrstate", "apple,t8103-pmgr-pwrstate";
				reg = <0x3d0 0x04>;
				#power-domain-cells = <0x00>;
				#reset-cells = <0x00>;
				label = "venc_sys";
				power-domains = <0x3b>;
				phandle = <0x54>;
			};

			power-controller@3d8 {
				compatible = "apple,t6030-pmgr-pwrstate", "apple,t8103-pmgr-pwrstate";
				reg = <0x3d8 0x04>;
				#power-domain-cells = <0x00>;
				#reset-cells = <0x00>;
				label = "dispext0_fe";
				power-domains = <0x3c>;
				phandle = <0x3d>;
			};

			power-controller@3e0 {
				compatible = "apple,t6030-pmgr-pwrstate", "apple,t8103-pmgr-pwrstate";
				reg = <0x3e0 0x04>;
				#power-domain-cells = <0x00>;
				#reset-cells = <0x00>;
				label = "dispext0_cpu";
				power-domains = <0x3d>;
			};

			power-controller@3e8 {
				compatible = "apple,t6030-pmgr-pwrstate", "apple,t8103-pmgr-pwrstate";
				reg = <0x3e8 0x04>;
				#power-domain-cells = <0x00>;
				#reset-cells = <0x00>;
				label = "trace_fab";
			};

			power-controller@3f0 {
				compatible = "apple,t6030-pmgr-pwrstate", "apple,t8103-pmgr-pwrstate";
				reg = <0x3f0 0x04>;
				#power-domain-cells = <0x00>;
				#reset-cells = <0x00>;
				label = "dispext1_fe";
				power-domains = <0x3e>;
				phandle = <0x3f>;
			};

			power-controller@3f8 {
				compatible = "apple,t6030-pmgr-pwrstate", "apple,t8103-pmgr-pwrstate";
				reg = <0x3f8 0x04>;
				#power-domain-cells = <0x00>;
				#reset-cells = <0x00>;
				label = "dispext1_cpu";
				power-domains = <0x3f>;
			};

			power-controller@408 {
				compatible = "apple,t6030-pmgr-pwrstate", "apple,t8103-pmgr-pwrstate";
				reg = <0x408 0x04>;
				#power-domain-cells = <0x00>;
				#reset-cells = <0x00>;
				label = "dptx_phy";
				apple,always-on;
			};

			power-controller@490 {
				compatible = "apple,t6030-pmgr-pwrstate", "apple,t8103-pmgr-pwrstate";
				reg = <0x490 0x04>;
				#power-domain-cells = <0x00>;
				#reset-cells = <0x00>;
				label = "avd_sys";
			};

			power-controller@498 {
				compatible = "apple,t6030-pmgr-pwrstate", "apple,t8103-pmgr-pwrstate";
				reg = <0x498 0x04>;
				#power-domain-cells = <0x00>;
				#reset-cells = <0x00>;
				label = "ane_sys";
			};

			power-controller@4a0 {
				compatible = "apple,t6030-pmgr-pwrstate", "apple,t8103-pmgr-pwrstate";
				reg = <0x4a0 0x04>;
				#power-domain-cells = <0x00>;
				#reset-cells = <0x00>;
				label = "scodec";
				phandle = <0x40>;
			};

			power-controller@4a8 {
				compatible = "apple,t6030-pmgr-pwrstate", "apple,t8103-pmgr-pwrstate";
				reg = <0x4a8 0x04>;
				#power-domain-cells = <0x00>;
				#reset-cells = <0x00>;
				label = "scodec_stream";
				power-domains = <0x40>;
			};

			power-controller@4b0 {
				compatible = "apple,t6030-pmgr-pwrstate", "apple,t8103-pmgr-pwrstate";
				reg = <0x4b0 0x04>;
				#power-domain-cells = <0x00>;
				#reset-cells = <0x00>;
				label = "ioa3";
				apple,always-on;
				phandle = <0x41>;
			};

			power-controller@4b8 {
				compatible = "apple,t6030-pmgr-pwrstate", "apple,t8103-pmgr-pwrstate";
				reg = <0x4b8 0x04>;
				#power-domain-cells = <0x00>;
				#reset-cells = <0x00>;
				label = "ls3";
				apple,always-on;
				power-domains = <0x41>;
				phandle = <0x42>;
			};

			power-controller@4c0 {
				compatible = "apple,t6030-pmgr-pwrstate", "apple,t8103-pmgr-pwrstate";
				reg = <0x4c0 0x04>;
				#power-domain-cells = <0x00>;
				#reset-cells = <0x00>;
				label = "lw30";
				apple,always-on;
				power-domains = <0x42>;
				phandle = <0x43>;
			};

			power-controller@4c8 {
				compatible = "apple,t6030-pmgr-pwrstate", "apple,t8103-pmgr-pwrstate";
				reg = <0x4c8 0x04>;
				#power-domain-cells = <0x00>;
				#reset-cells = <0x00>;
				label = "pmp";
			};

			power-controller@4d0 {
				compatible = "apple,t6030-pmgr-pwrstate", "apple,t8103-pmgr-pwrstate";
				reg = <0x4d0 0x04>;
				#power-domain-cells = <0x00>;
				#reset-cells = <0x00>;
				label = "pms_sram";
			};

			power-controller@4d8 {
				compatible = "apple,t6030-pmgr-pwrstate", "apple,t8103-pmgr-pwrstate";
				reg = <0x4d8 0x04>;
				#power-domain-cells = <0x00>;
				#reset-cells = <0x00>;
				label = "lw31";
				apple,always-on;
				power-domains = <0x42>;
				phandle = <0x44>;
			};

			power-controller@4e0 {
				compatible = "apple,t6030-pmgr-pwrstate", "apple,t8103-pmgr-pwrstate";
				reg = <0x4e0 0x04>;
				#power-domain-cells = <0x00>;
				#reset-cells = <0x00>;
				label = "atc0_common";
				power-domains = <0x43>;
				phandle = <0x45>;
			};

			power-controller@4e8 {
				compatible = "apple,t6030-pmgr-pwrstate", "apple,t8103-pmgr-pwrstate";
				reg = <0x4e8 0x04>;
				#power-domain-cells = <0x00>;
				#reset-cells = <0x00>;
				label = "atc1_common";
				power-domains = <0x43>;
				phandle = <0x46>;
			};

			power-controller@4f0 {
				compatible = "apple,t6030-pmgr-pwrstate", "apple,t8103-pmgr-pwrstate";
				reg = <0x4f0 0x04>;
				#power-domain-cells = <0x00>;
				#reset-cells = <0x00>;
				label = "atc2_common";
				power-domains = <0x43>;
				phandle = <0x47>;
			};

			power-controller@4f8 {
				compatible = "apple,t6030-pmgr-pwrstate", "apple,t8103-pmgr-pwrstate";
				reg = <0x4f8 0x04>;
				#power-domain-cells = <0x00>;
				#reset-cells = <0x00>;
				label = "atc3_common";
				power-domains = <0x43>;
				phandle = <0x48>;
			};

			power-controller@500 {
				compatible = "apple,t6030-pmgr-pwrstate", "apple,t8103-pmgr-pwrstate";
				reg = <0x500 0x04>;
				#power-domain-cells = <0x00>;
				#reset-cells = <0x00>;
				label = "apcie_gp";
				power-domains = <0x44>;
				phandle = <0x49>;
			};

			power-controller@508 {
				compatible = "apple,t6030-pmgr-pwrstate", "apple,t8103-pmgr-pwrstate";
				reg = <0x508 0x04>;
				#power-domain-cells = <0x00>;
				#reset-cells = <0x00>;
				label = "msr";
				power-domains = <0x44>;
				phandle = <0x4a>;
			};

			power-controller@510 {
				compatible = "apple,t6030-pmgr-pwrstate", "apple,t8103-pmgr-pwrstate";
				reg = <0x510 0x04>;
				#power-domain-cells = <0x00>;
				#reset-cells = <0x00>;
				label = "ans";
				power-domains = <0x44>;
				phandle = <0x4b>;
			};

			power-controller@518 {
				compatible = "apple,t6030-pmgr-pwrstate", "apple,t8103-pmgr-pwrstate";
				reg = <0x518 0x04>;
				#power-domain-cells = <0x00>;
				#reset-cells = <0x00>;
				label = "atc0_pcie";
				power-domains = <0x45>;
			};

			power-controller@520 {
				compatible = "apple,t6030-pmgr-pwrstate", "apple,t8103-pmgr-pwrstate";
				reg = <0x520 0x04>;
				#power-domain-cells = <0x00>;
				#reset-cells = <0x00>;
				label = "atc0_cio";
				power-domains = <0x45>;
				phandle = <0x4c>;
			};

			power-controller@528 {
				compatible = "apple,t6030-pmgr-pwrstate", "apple,t8103-pmgr-pwrstate";
				reg = <0x528 0x04>;
				#power-domain-cells = <0x00>;
				#reset-cells = <0x00>;
				label = "atc1_pcie";
				power-domains = <0x46>;
			};

			power-controller@530 {
				compatible = "apple,t6030-pmgr-pwrstate", "apple,t8103-pmgr-pwrstate";
				reg = <0x530 0x04>;
				#power-domain-cells = <0x00>;
				#reset-cells = <0x00>;
				label = "atc1_cio";
				power-domains = <0x46>;
				phandle = <0x4d>;
			};

			power-controller@538 {
				compatible = "apple,t6030-pmgr-pwrstate", "apple,t8103-pmgr-pwrstate";
				reg = <0x538 0x04>;
				#power-domain-cells = <0x00>;
				#reset-cells = <0x00>;
				label = "atc2_pcie";
				power-domains = <0x47>;
			};

			power-controller@540 {
				compatible = "apple,t6030-pmgr-pwrstate", "apple,t8103-pmgr-pwrstate";
				reg = <0x540 0x04>;
				#power-domain-cells = <0x00>;
				#reset-cells = <0x00>;
				label = "atc2_cio";
				power-domains = <0x47>;
				phandle = <0x4e>;
			};

			power-controller@548 {
				compatible = "apple,t6030-pmgr-pwrstate", "apple,t8103-pmgr-pwrstate";
				reg = <0x548 0x04>;
				#power-domain-cells = <0x00>;
				#reset-cells = <0x00>;
				label = "atc3_pcie";
				power-domains = <0x48>;
			};

			power-controller@550 {
				compatible = "apple,t6030-pmgr-pwrstate", "apple,t8103-pmgr-pwrstate";
				reg = <0x550 0x04>;
				#power-domain-cells = <0x00>;
				#reset-cells = <0x00>;
				label = "atc3_cio";
				power-domains = <0x48>;
				phandle = <0x4f>;
			};

			power-controller@558 {
				compatible = "apple,t6030-pmgr-pwrstate", "apple,t8103-pmgr-pwrstate";
				reg = <0x558 0x04>;
				#power-domain-cells = <0x00>;
				#reset-cells = <0x00>;
				label = "apcie_sys_gp";
				power-domains = <0x49>;
				phandle = <0x72>;
			};

			power-controller@560 {
				compatible = "apple,t6030-pmgr-pwrstate", "apple,t8103-pmgr-pwrstate";
				reg = <0x560 0x04>;
				#power-domain-cells = <0x00>;
				#reset-cells = <0x00>;
				label = "msr_ase_core";
				power-domains = <0x4a>;
			};

			power-controller@568 {
				compatible = "apple,t6030-pmgr-pwrstate", "apple,t8103-pmgr-pwrstate";
				reg = <0x568 0x04>;
				#power-domain-cells = <0x00>;
				#reset-cells = <0x00>;
				label = "apcie_st";
				power-domains = <0x4b>;
				phandle = <0x50>;
			};

			power-controller@570 {
				compatible = "apple,t6030-pmgr-pwrstate", "apple,t8103-pmgr-pwrstate";
				reg = <0x570 0x04>;
				#power-domain-cells = <0x00>;
				#reset-cells = <0x00>;
				label = "atc0_cio_pcie";
				power-domains = <0x4c>;
			};

			power-controller@578 {
				compatible = "apple,t6030-pmgr-pwrstate", "apple,t8103-pmgr-pwrstate";
				reg = <0x578 0x04>;
				#power-domain-cells = <0x00>;
				#reset-cells = <0x00>;
				label = "atc0_cio_usb";
				power-domains = <0x4c>;
			};

			power-controller@580 {
				compatible = "apple,t6030-pmgr-pwrstate", "apple,t8103-pmgr-pwrstate";
				reg = <0x580 0x04>;
				#power-domain-cells = <0x00>;
				#reset-cells = <0x00>;
				label = "atc1_cio_pcie";
				power-domains = <0x4d>;
			};

			power-controller@588 {
				compatible = "apple,t6030-pmgr-pwrstate", "apple,t8103-pmgr-pwrstate";
				reg = <0x588 0x04>;
				#power-domain-cells = <0x00>;
				#reset-cells = <0x00>;
				label = "atc1_cio_usb";
				power-domains = <0x4d>;
			};

			power-controller@590 {
				compatible = "apple,t6030-pmgr-pwrstate", "apple,t8103-pmgr-pwrstate";
				reg = <0x590 0x04>;
				#power-domain-cells = <0x00>;
				#reset-cells = <0x00>;
				label = "atc2_cio_pcie";
				power-domains = <0x4e>;
			};

			power-controller@598 {
				compatible = "apple,t6030-pmgr-pwrstate", "apple,t8103-pmgr-pwrstate";
				reg = <0x598 0x04>;
				#power-domain-cells = <0x00>;
				#reset-cells = <0x00>;
				label = "atc2_cio_usb";
				power-domains = <0x4e>;
			};

			power-controller@5a0 {
				compatible = "apple,t6030-pmgr-pwrstate", "apple,t8103-pmgr-pwrstate";
				reg = <0x5a0 0x04>;
				#power-domain-cells = <0x00>;
				#reset-cells = <0x00>;
				label = "atc3_cio_pcie";
				power-domains = <0x4f>;
			};

			power-controller@5a8 {
				compatible = "apple,t6030-pmgr-pwrstate", "apple,t8103-pmgr-pwrstate";
				reg = <0x5a8 0x04>;
				#power-domain-cells = <0x00>;
				#reset-cells = <0x00>;
				label = "atc3_cio_usb";
				power-domains = <0x4f>;
			};

			power-controller@5b0 {
				compatible = "apple,t6030-pmgr-pwrstate", "apple,t8103-pmgr-pwrstate";
				reg = <0x5b0 0x04>;
				#power-domain-cells = <0x00>;
				#reset-cells = <0x00>;
				label = "apcie_sys_st";
				power-domains = <0x50 0x4b>;
				phandle = <0x6c>;
			};

			power-controller@5b8 {
				compatible = "apple,t6030-pmgr-pwrstate", "apple,t8103-pmgr-pwrstate";
				reg = <0x5b8 0x04>;
				#power-domain-cells = <0x00>;
				#reset-cells = <0x00>;
				label = "apcie_phy_sw";
				apple,always-on;
			};

			power-controller@c00 {
				compatible = "apple,t6030-pmgr-pwrstate", "apple,t8103-pmgr-pwrstate";
				reg = <0xc00 0x04>;
				#power-domain-cells = <0x00>;
				#reset-cells = <0x00>;
				label = "sep";
				apple,always-on;
			};

			power-controller@4000 {
				compatible = "apple,t6030-pmgr-pwrstate", "apple,t8103-pmgr-pwrstate";
				reg = <0x4000 0x04>;
				#power-domain-cells = <0x00>;
				#reset-cells = <0x00>;
				label = "isp_cpu";
				power-domains = <0x51>;
			};

			power-controller@4008 {
				compatible = "apple,t6030-pmgr-pwrstate", "apple,t8103-pmgr-pwrstate";
				reg = <0x4008 0x04>;
				#power-domain-cells = <0x00>;
				#reset-cells = <0x00>;
				label = "isp_fe";
				power-domains = <0x51>;
				phandle = <0x52>;
			};

			power-controller@4010 {
				compatible = "apple,t6030-pmgr-pwrstate", "apple,t8103-pmgr-pwrstate";
				reg = <0x4010 0x04>;
				#power-domain-cells = <0x00>;
				#reset-cells = <0x00>;
				label = "dprx";
				power-domains = <0x52>;
			};

			power-controller@4018 {
				compatible = "apple,t6030-pmgr-pwrstate", "apple,t8103-pmgr-pwrstate";
				reg = <0x4018 0x04>;
				#power-domain-cells = <0x00>;
				#reset-cells = <0x00>;
				label = "isp_secure";
				power-domains = <0x52>;
			};

			power-controller@4020 {
				compatible = "apple,t6030-pmgr-pwrstate", "apple,t8103-pmgr-pwrstate";
				reg = <0x4020 0x04>;
				#power-domain-cells = <0x00>;
				#reset-cells = <0x00>;
				label = "isp_be";
				power-domains = <0x52>;
				phandle = <0x53>;
			};

			power-controller@4028 {
				compatible = "apple,t6030-pmgr-pwrstate", "apple,t8103-pmgr-pwrstate";
				reg = <0x4028 0x04>;
				#power-domain-cells = <0x00>;
				#reset-cells = <0x00>;
				label = "isp_clr";
				power-domains = <0x53>;
			};

			power-controller@8000 {
				compatible = "apple,t6030-pmgr-pwrstate", "apple,t8103-pmgr-pwrstate";
				reg = <0x8000 0x04>;
				#power-domain-cells = <0x00>;
				#reset-cells = <0x00>;
				label = "venc_dma";
				power-domains = <0x54>;
				phandle = <0x55>;
			};

			power-controller@8008 {
				compatible = "apple,t6030-pmgr-pwrstate", "apple,t8103-pmgr-pwrstate";
				reg = <0x8008 0x04>;
				#power-domain-cells = <0x00>;
				#reset-cells = <0x00>;
				label = "venc_pipe4";
				power-domains = <0x55>;
			};

			power-controller@8010 {
				compatible = "apple,t6030-pmgr-pwrstate", "apple,t8103-pmgr-pwrstate";
				reg = <0x8010 0x04>;
				#power-domain-cells = <0x00>;
				#reset-cells = <0x00>;
				label = "venc_pipe5";
				power-domains = <0x55>;
			};

			power-controller@8018 {
				compatible = "apple,t6030-pmgr-pwrstate", "apple,t8103-pmgr-pwrstate";
				reg = <0x8018 0x04>;
				#power-domain-cells = <0x00>;
				#reset-cells = <0x00>;
				label = "venc_me0";
				power-domains = <0x55>;
				phandle = <0x56>;
			};

			power-controller@8020 {
				compatible = "apple,t6030-pmgr-pwrstate", "apple,t8103-pmgr-pwrstate";
				reg = <0x8020 0x04>;
				#power-domain-cells = <0x00>;
				#reset-cells = <0x00>;
				label = "venc_me1";
				power-domains = <0x56>;
			};

			power-controller@10000 {
				compatible = "apple,t6030-pmgr-pwrstate", "apple,t8103-pmgr-pwrstate";
				reg = <0x10000 0x04>;
				#power-domain-cells = <0x00>;
				#reset-cells = <0x00>;
				label = "disp_cpu";
				power-domains = <0x57>;
				apple,min-state = <0x04>;
				phandle = <0x79>;
			};
		};

		clock-controller@350044000 {
			compatible = "apple,t6030-nco", "apple,t8103-nco";
			reg = <0x03 0x50044000 0x00 0x14000>;
			clocks = <0x58>;
			#clock-cells = <0x01>;
			phandle = <0x2c>;
		};

		interrupt-controller@351000000 {
			compatible = "apple,t6030-aic3", "apple,t8122-aic3";
			#interrupt-cells = <0x03>;
			interrupt-controller;
			reg = <0x03 0x51000000 0x00 0x184000 0x03 0x51040000 0x00 0x4000>;
			reg-names = "core", "event";
			power-domains = <0x59>;
			phandle = <0x13>;
		};

		pinctrl@3641f0000 {
			compatible = "apple,t6030-pinctrl", "apple,t8103-pinctrl";
			reg = <0x03 0x641f0000 0x00 0x4000>;
			interrupt-parent = <0x13>;
			interrupts = <0x00 0x1d8 0x04 0x00 0x1d9 0x04 0x00 0x1da 0x04 0x00 0x1db 0x04 0x00 0x1dc 0x04 0x00 0x1dd 0x04 0x00 0x1de 0x04>;
			gpio-controller;
			#gpio-cells = <0x02>;
			gpio-ranges = <0x18 0x00 0x00 0x25>;
			apple,npins = <0x25>;
			interrupt-controller;
			#interrupt-cells = <0x02>;
			phandle = <0x1b>;
		};

		power-management@364280000 {
			compatible = "apple,t6030-pmgr", "apple,t8103-pmgr", "syscon", "simple-mfd";
			#address-cells = <0x01>;
			#size-cells = <0x01>;
			reg = <0x03 0x64280000 0x00 0x4000>;

			power-controller@0 {
				compatible = "apple,t6030-pmgr-pwrstate", "apple,t8103-pmgr-pwrstate";
				reg = <0x00 0x04>;
				#power-domain-cells = <0x00>;
				#reset-cells = <0x00>;
				label = "debug_gated";
				apple,always-on;
			};

			power-controller@58 {
				compatible = "apple,t6030-pmgr-pwrstate", "apple,t8103-pmgr-pwrstate";
				reg = <0x58 0x04>;
				#power-domain-cells = <0x00>;
				#reset-cells = <0x00>;
				label = "nub_spmi0";
				apple,always-on;
			};

			power-controller@60 {
				compatible = "apple,t6030-pmgr-pwrstate", "apple,t8103-pmgr-pwrstate";
				reg = <0x60 0x04>;
				#power-domain-cells = <0x00>;
				#reset-cells = <0x00>;
				label = "nub_spmi1";
				apple,always-on;
			};

			power-controller@68 {
				compatible = "apple,t6030-pmgr-pwrstate", "apple,t8103-pmgr-pwrstate";
				reg = <0x68 0x04>;
				#power-domain-cells = <0x00>;
				#reset-cells = <0x00>;
				label = "nub_spmi2";
				apple,always-on;
			};

			power-controller@70 {
				compatible = "apple,t6030-pmgr-pwrstate", "apple,t8103-pmgr-pwrstate";
				reg = <0x70 0x04>;
				#power-domain-cells = <0x00>;
				#reset-cells = <0x00>;
				label = "nub_spmi_a0";
				apple,always-on;
			};

			power-controller@78 {
				compatible = "apple,t6030-pmgr-pwrstate", "apple,t8103-pmgr-pwrstate";
				reg = <0x78 0x04>;
				#power-domain-cells = <0x00>;
				#reset-cells = <0x00>;
				label = "nub_spmi_a1";
				apple,always-on;
			};

			power-controller@88 {
				compatible = "apple,t6030-pmgr-pwrstate", "apple,t8103-pmgr-pwrstate";
				reg = <0x88 0x04>;
				#power-domain-cells = <0x00>;
				#reset-cells = <0x00>;
				label = "nub_spi0";
				apple,always-on;
			};

			power-controller@90 {
				compatible = "apple,t6030-pmgr-pwrstate", "apple,t8103-pmgr-pwrstate";
				reg = <0x90 0x04>;
				#power-domain-cells = <0x00>;
				#reset-cells = <0x00>;
				label = "nub_ocla";
				apple,always-on;
			};

			power-controller@98 {
				compatible = "apple,t6030-pmgr-pwrstate", "apple,t8103-pmgr-pwrstate";
				reg = <0x98 0x04>;
				#power-domain-cells = <0x00>;
				#reset-cells = <0x00>;
				label = "nub_gpio";
				apple,always-on;
			};

			power-controller@a8 {
				compatible = "apple,t6030-pmgr-pwrstate", "apple,t8103-pmgr-pwrstate";
				reg = <0xa8 0x04>;
				#power-domain-cells = <0x00>;
				#reset-cells = <0x00>;
				label = "nub_sram";
				apple,always-on;
			};

			power-controller@b0 {
				compatible = "apple,t6030-pmgr-pwrstate", "apple,t8103-pmgr-pwrstate";
				reg = <0xb0 0x04>;
				#power-domain-cells = <0x00>;
				#reset-cells = <0x00>;
				label = "debug_switch";
				apple,always-on;
			};

			power-controller@b8 {
				compatible = "apple,t6030-pmgr-pwrstate", "apple,t8103-pmgr-pwrstate";
				reg = <0xb8 0x04>;
				#power-domain-cells = <0x00>;
				#reset-cells = <0x00>;
				label = "atc0_usb_aon";
				phandle = <0x5a>;
			};

			power-controller@c0 {
				compatible = "apple,t6030-pmgr-pwrstate", "apple,t8103-pmgr-pwrstate";
				reg = <0xc0 0x04>;
				#power-domain-cells = <0x00>;
				#reset-cells = <0x00>;
				label = "atc1_usb_aon";
				phandle = <0x5b>;
			};

			power-controller@c8 {
				compatible = "apple,t6030-pmgr-pwrstate", "apple,t8103-pmgr-pwrstate";
				reg = <0xc8 0x04>;
				#power-domain-cells = <0x00>;
				#reset-cells = <0x00>;
				label = "atc2_usb_aon";
				phandle = <0x5c>;
			};

			power-controller@d0 {
				compatible = "apple,t6030-pmgr-pwrstate", "apple,t8103-pmgr-pwrstate";
				reg = <0xd0 0x04>;
				#power-domain-cells = <0x00>;
				#reset-cells = <0x00>;
				label = "atc3_usb_aon";
				phandle = <0x5d>;
			};

			power-controller@d8 {
				compatible = "apple,t6030-pmgr-pwrstate", "apple,t8103-pmgr-pwrstate";
				reg = <0xd8 0x04>;
				#power-domain-cells = <0x00>;
				#reset-cells = <0x00>;
				label = "atc0_usb";
				power-domains = <0x5a 0x45>;
			};

			power-controller@e0 {
				compatible = "apple,t6030-pmgr-pwrstate", "apple,t8103-pmgr-pwrstate";
				reg = <0xe0 0x04>;
				#power-domain-cells = <0x00>;
				#reset-cells = <0x00>;
				label = "atc1_usb";
				power-domains = <0x5b 0x46>;
			};

			power-controller@e8 {
				compatible = "apple,t6030-pmgr-pwrstate", "apple,t8103-pmgr-pwrstate";
				reg = <0xe8 0x04>;
				#power-domain-cells = <0x00>;
				#reset-cells = <0x00>;
				label = "atc2_usb";
				power-domains = <0x5c 0x47>;
			};

			power-controller@f0 {
				compatible = "apple,t6030-pmgr-pwrstate", "apple,t8103-pmgr-pwrstate";
				reg = <0xf0 0x04>;
				#power-domain-cells = <0x00>;
				#reset-cells = <0x00>;
				label = "atc3_usb";
				power-domains = <0x5d 0x48>;
			};
		};

		watchdog@3642b0000 {
			compatible = "apple,t6030-wdt", "apple,t8103-wdt";
			reg = <0x03 0x642b0000 0x00 0x4000>;
			clocks = <0x14>;
			interrupt-parent = <0x13>;
			interrupts = <0x00 0x1e0 0x04>;
		};

		spmi@364714000 {
			compatible = "apple,t6030-spmi", "apple,t8103-spmi";
			reg = <0x03 0x64714000 0x00 0x100>;
			#address-cells = <0x02>;
			#size-cells = <0x00>;

			pmic@b {
				compatible = "apple,chapel-pmic", "apple,spmi-nvmem";
				reg = <0x0b 0x00>;

				nvmem-layout {
					compatible = "fixed-layout";
					#address-cells = <0x01>;
					#size-cells = <0x01>;

					pm-setting@2001 {
						reg = <0x2001 0x01>;
					};

					rtc-offset@2100 {
						reg = <0x2100 0x06>;
						phandle = <0x63>;
					};

					fault-shadow@867b {
						reg = <0x867b 0x10>;
					};

					socd@8b00 {
						reg = <0x8b00 0x400>;
					};

					boot-stage@f801 {
						reg = <0xf801 0x01>;
						phandle = <0x60>;
					};

					boot-error-count@f802,0 {
						reg = <0xf802 0x01>;
						bits = <0x00 0x04>;
						phandle = <0x61>;
					};

					panic-count@f802,4 {
						reg = <0xf802 0x01>;
						bits = <0x04 0x04>;
						phandle = <0x62>;
					};

					boot-error-stage@f803 {
						reg = <0xf803 0x01>;
					};

					shutdown-flag@f80f,3 {
						reg = <0xf80f 0x01>;
						bits = <0x03 0x01>;
						phandle = <0x5f>;
					};
				};
			};
		};

		mbox@36c408000 {
			compatible = "apple,t6030-asc-mailbox", "apple,asc-mailbox-v4";
			reg = <0x03 0x6c408000 0x00 0x4000>;
			interrupt-parent = <0x13>;
			interrupts = <0x00 0x22a 0x04 0x00 0x22b 0x04 0x00 0x22c 0x04 0x00 0x22d 0x04>;
			interrupt-names = "send-empty", "send-not-empty", "recv-empty", "recv-not-empty";
			#mbox-cells = <0x00>;
			phandle = <0x5e>;
		};

		smc@36c400000 {
			compatible = "apple,t6030-smc", "apple,t8103-smc";
			reg = <0x03 0x6c400000 0x00 0x4000 0x03 0x6de00000 0x00 0x100000>;
			reg-names = "smc", "sram";
			mboxes = <0x5e>;

			gpio@67500000 {
				compatible = "apple,smc-gpio";
				gpio-controller;
				#gpio-cells = <0x02>;
				phandle = <0x75>;
			};

			gpio@67700000 {
				compatible = "apple,smc-low-gpio";
				gpio-controller;
				#gpio-cells = <0x02>;
				phandle = <0x69>;
			};

			hwmon {
				compatible = "apple,smc-hwmon";

				power-PSTR {
					apple,key-id = "PSTR";
					label = "Total System Power";
				};

				power-PDTR {
					apple,key-id = "PDTR";
					label = "AC Input Power";
				};

				power-PMVR {
					apple,key-id = "PMVR";
					label = "3.8 V Rail Power";
				};

				temperature-TH0x {
					apple,key-id = "TH0x";
					label = "NAND Flash Temperature";
				};

				voltage-VD0R {
					apple,key-id = "VD0R";
					label = "Charger Input Voltage";
				};

				current-ID0R {
					apple,key-id = "ID0R";
					label = "AC Input Current";
				};

				fan-F0Ac {
					apple,key-id = "F0Ac";
					label = "Fan 1";
					apple,fan-minimum = "F0Mn";
					apple,fan-maximum = "F0Mx";
					apple,fan-target = "F0Tg";
					apple,fan-mode = "F0Md";
				};

				fan-F1Ac {
					apple,key-id = "F1Ac";
					label = "Fan 2";
					apple,fan-minimum = "F1Mn";
					apple,fan-maximum = "F1Mx";
					apple,fan-target = "F1Tg";
					apple,fan-mode = "F1Md";
				};

				power-PHPC {
					apple,key-id = "PHPC";
					label = "Heatpipe Power";
				};

				temperature-TB0T {
					apple,key-id = "TB0T";
					label = "Battery Hotspot";
				};

				temperature-TCHP {
					apple,key-id = "TCHP";
					label = "Charge Regulator Temp";
				};

				temperature-TW0P {
					apple,key-id = "TW0P";
					label = "WiFi/BT Module Temp";
				};

				voltage-SBAV {
					apple,key-id = "SBAV";
					label = "Battery Voltage";
				};
			};

			reboot {
				compatible = "apple,smc-reboot";
				nvmem-cells = <0x5f 0x60 0x61 0x62>;
				nvmem-cell-names = "shutdown_flag", "boot_stage", "boot_error_count", "panic_count";
			};

			rtc {
				compatible = "apple,smc-rtc";
				nvmem-cells = <0x63>;
				nvmem-cell-names = "rtc_offset";
			};
		};

		pinctrl@36c820000 {
			compatible = "apple,t6030-pinctrl", "apple,t8103-pinctrl";
			reg = <0x03 0x6c820000 0x00 0x4000>;
			gpio-controller;
			#gpio-cells = <0x02>;
			gpio-ranges = <0x64 0x00 0x00 0x12>;
			apple,npins = <0x12>;
			interrupt-controller;
			#interrupt-cells = <0x02>;
			interrupt-parent = <0x13>;
			interrupts = <0x00 0x221 0x04 0x00 0x222 0x04 0x00 0x223 0x04 0x00 0x224 0x04 0x00 0x225 0x04 0x00 0x226 0x04 0x00 0x227 0x04>;
			phandle = <0x64>;
		};

		pinctrl@374824000 {
			compatible = "apple,t6030-pinctrl", "apple,t8103-pinctrl";
			reg = <0x03 0x74824000 0x00 0x4000>;
			interrupt-parent = <0x13>;
			interrupts = <0x00 0x18a 0x04 0x00 0x18b 0x04 0x00 0x18c 0x04 0x00 0x18d 0x04 0x00 0x18e 0x04 0x00 0x18f 0x04 0x00 0x190 0x04>;
			clocks = <0x14>;
			gpio-controller;
			#gpio-cells = <0x02>;
			gpio-ranges = <0x18 0x00 0x00 0x36>;
			apple,npins = <0x36>;
			interrupt-controller;
			#interrupt-cells = <0x02>;
		};

		mtp@37a400000 {
			compatible = "apple,t6030-mtp", "apple,t6030-rtk-helper-asc4", "apple,mtp", "apple,rtk-helper-asc4";
			reg = <0x03 0x7a400000 0x00 0x4000 0x03 0x7ac00000 0x00 0x100000>;
			reg-names = "asc", "sram";
			mboxes = <0x65>;
			iommus = <0x66 0x01>;
			#helper-cells = <0x00>;
			status = "okay";
			phandle = <0x68>;
		};

		mbox@37a408000 {
			compatible = "apple,t6030-asc-mailbox", "apple,asc-mailbox-v4";
			reg = <0x03 0x7a408000 0x00 0x4000>;
			interrupt-parent = <0x13>;
			interrupts = <0x00 0x3b9 0x04 0x00 0x3ba 0x04 0x00 0x3bb 0x04 0x00 0x3bc 0x04>;
			interrupt-names = "send-empty", "send-not-empty", "recv-empty", "recv-not-empty";
			#mbox-cells = <0x00>;
			status = "okay";
			phandle = <0x65>;
		};

		iommu@37a808000 {
			compatible = "apple,t6030-dart", "apple,t8110-dart";
			reg = <0x03 0x7a808000 0x00 0x4000>;
			interrupt-parent = <0x13>;
			interrupts = <0x00 0x3a9 0x04>;
			#iommu-cells = <0x01>;
			status = "okay";
			phandle = <0x66>;
		};

		fifo@37ab30000 {
			compatible = "apple,t6030-dockchannel", "apple,dockchannel";
			reg = <0x03 0x7ab14000 0x00 0x4000>;
			reg-names = "irq";
			interrupt-parent = <0x13>;
			interrupts = <0x00 0x3ab 0x04>;
			ranges = <0x00 0x03 0x7ab28000 0x20000>;
			nonposted-mmio;
			#address-cells = <0x01>;
			#size-cells = <0x01>;
			interrupt-controller;
			#interrupt-cells = <0x02>;
			status = "okay";
			phandle = <0x67>;

			input@0 {
				compatible = "apple,dockchannel-hid";
				reg = <0x00 0x4000 0x4000 0x4000 0x8000 0x4000 0xc000 0x4000>;
				reg-names = "rmt-config", "rmt-data", "config", "data";
				iommus = <0x66 0x01>;
				interrupt-parent = <0x67>;
				interrupts = <0x02 0x04 0x03 0x04>;
				interrupt-names = "tx", "rx";
				apple,fifo-size = <0x800>;
				apple,helper-cpu = <0x68>;
				apple,afe-reset-gpios = <0x69 0x19 0x01>;
				apple,stm-reset-gpios = <0x69 0x1a 0x01>;

				multi-touch {
					firmware-name = "apple/tpmtfw-j514s.bin";
				};

				keyboard {
					hid-country-code = <0x00>;
					apple,keyboard-layout-id = <0x00>;
				};

				stm {
				};

				actuator {
				};

				tp_accel {
				};
			};
		};

		mbox@389408000 {
			compatible = "apple,t6030-asc-mailbox", "apple,asc-mailbox-v4";
			reg = <0x03 0x89408000 0x00 0x4000>;
			interrupt-parent = <0x13>;
			interrupts = <0x00 0x347 0x04 0x00 0x348 0x04 0x00 0x349 0x04 0x00 0x34a 0x04>;
			interrupt-names = "send-empty", "send-not-empty", "recv-empty", "recv-not-empty";
			#mbox-cells = <0x00>;
			power-domains = <0x4b>;
			phandle = <0x6a>;
		};

		sart@38dc50000 {
			compatible = "apple,t6030-sart", "apple,t6000-sart";
			reg = <0x03 0x8dc50000 0x00 0xc000>;
			power-domains = <0x4b>;
			phandle = <0x6b>;
		};

		nvme@38dcc0000 {
			compatible = "apple,t6030-nvme-ans3", "apple,t8103-nvme-ans2";
			reg = <0x03 0x8dcc0000 0x00 0x60000 0x03 0x89400000 0x00 0x4000>;
			reg-names = "nvme", "ans";
			interrupt-parent = <0x13>;
			interrupts = <0x00 0x353 0x04>;
			mboxes = <0x6a>;
			apple,sart = <0x6b>;
			power-domains = <0x4b 0x6c>;
			power-domain-names = "ans", "apcie0";
			resets = <0x4b>;
		};

		pcie@580000000 {
			compatible = "apple,t6030-pcie", "apple,t6020-pcie";
			device_type = "pci";
			reg = <0x05 0x80000000 0x00 0x1000000 0x05 0x91000000 0x00 0x4000 0x05 0x94008000 0x00 0x4000 0x05 0x95008000 0x00 0x4000 0x05 0x96008000 0x00 0x4000 0x05 0x97008000 0x00 0x4000 0x05 0x9e020000 0x00 0x4000 0x05 0x9e024000 0x00 0x4000 0x05 0x9e028000 0x00 0x4000 0x05 0x9e02c000 0x00 0x4000>;
			reg-names = "config", "rc", "port0", "port1", "port2", "port3", "phy0", "phy1", "phy2", "phy3";
			interrupt-parent = <0x13>;
			interrupts = <0x00 0x40e 0x04 0x00 0x417 0x04 0x00 0x420 0x04 0x00 0x429 0x04>;
			msi-controller;
			msi-parent = <0x6d>;
			msi-ranges = <0x13 0x00 0x53e 0x01 0x20>;
			iommu-map = <0x100 0x6e 0x01 0x01 0x200 0x6f 0x01 0x01 0x300 0x70 0x01 0x01 0x400 0x71 0x01 0x01>;
			iommu-map-mask = <0xff00>;
			bus-range = <0x00 0x04>;
			#address-cells = <0x03>;
			#size-cells = <0x02>;
			ranges = <0x43000000 0x05 0xa0000000 0x05 0xa0000000 0x00 0x20000000 0x2000000 0x00 0xc0000000 0x05 0xc0000000 0x00 0x40000000>;
			power-domains = <0x72>;
			pinctrl-0 = <0x73>;
			pinctrl-names = "default";
			phandle = <0x6d>;

			pci@0,0 {
				device_type = "pci";
				reg = <0x00 0x00 0x00 0x00 0x00>;
				reset-gpios = <0x18 0xa7 0x01>;
				#address-cells = <0x03>;
				#size-cells = <0x02>;
				ranges;
				interrupt-controller;
				#interrupt-cells = <0x01>;
				interrupt-map-mask = <0x00 0x00 0x00 0x07>;
				interrupt-map = <0x00 0x00 0x00 0x01 0x74 0x00 0x00 0x00 0x00 0x00 0x00 0x00 0x02 0x74 0x00 0x00 0x00 0x01 0x00 0x00 0x00 0x03 0x74 0x00 0x00 0x00 0x02 0x00 0x00 0x00 0x04 0x74 0x00 0x00 0x00 0x03>;
				bus-range = <0x01 0x01>;
				pwren-gpios = <0x75 0x13 0x00>;
				phandle = <0x74>;

				wifi@0,0 {
					compatible = "pci14e4,4433";
					reg = <0x10000 0x00 0x00 0x00 0x00>;
					local-mac-address = [00 10 18 00 00 10];
					apple,antenna-sku = "XX";
					brcm,board-type = "apple,texa";
				};

				bluetooth@0,1 {
					compatible = "pci14e4,5f71";
					reg = <0x10100 0x00 0x00 0x00 0x00>;
					local-bd-address = [00 00 00 00 00 00];
					brcm,board-type = "apple,texa";
				};
			};

			pci@1,0 {
				device_type = "pci";
				reg = <0x800 0x00 0x00 0x00 0x00>;
				reset-gpios = <0x18 0xa8 0x01>;
				#address-cells = <0x03>;
				#size-cells = <0x02>;
				ranges;
				interrupt-controller;
				#interrupt-cells = <0x01>;
				interrupt-map-mask = <0x00 0x00 0x00 0x07>;
				interrupt-map = <0x00 0x00 0x00 0x01 0x76 0x00 0x00 0x00 0x00 0x00 0x00 0x00 0x02 0x76 0x00 0x00 0x00 0x01 0x00 0x00 0x00 0x03 0x76 0x00 0x00 0x00 0x02 0x00 0x00 0x00 0x04 0x76 0x00 0x00 0x00 0x03>;
				status = "okay";
				bus-range = <0x02 0x02>;
				pwren-gpios = <0x75 0x19 0x00>;
				phandle = <0x76>;

				mmc@0,0 {
					compatible = "pci17a0,9755";
					reg = <0x20000 0x00 0x00 0x00 0x00>;
					cd-inverted;
					wp-inverted;
				};
			};

			pci@2,0 {
				device_type = "pci";
				reg = <0x1000 0x00 0x00 0x00 0x00>;
				reset-gpios = <0x18 0xa9 0x01>;
				#address-cells = <0x03>;
				#size-cells = <0x02>;
				ranges;
				interrupt-controller;
				#interrupt-cells = <0x01>;
				interrupt-map-mask = <0x00 0x00 0x00 0x07>;
				interrupt-map = <0x00 0x00 0x00 0x01 0x77 0x00 0x00 0x00 0x00 0x00 0x00 0x00 0x02 0x77 0x00 0x00 0x00 0x01 0x00 0x00 0x00 0x03 0x77 0x00 0x00 0x00 0x02 0x00 0x00 0x00 0x04 0x77 0x00 0x00 0x00 0x03>;
				status = "disabled";
				phandle = <0x77>;
			};

			pci@3,0 {
				device_type = "pci";
				reg = <0x1800 0x00 0x00 0x00 0x00>;
				reset-gpios = <0x18 0xaa 0x01>;
				#address-cells = <0x03>;
				#size-cells = <0x02>;
				ranges;
				interrupt-controller;
				#interrupt-cells = <0x01>;
				interrupt-map-mask = <0x00 0x00 0x00 0x07>;
				interrupt-map = <0x00 0x00 0x00 0x01 0x78 0x00 0x00 0x00 0x00 0x00 0x00 0x00 0x02 0x78 0x00 0x00 0x00 0x01 0x00 0x00 0x00 0x03 0x78 0x00 0x00 0x00 0x02 0x00 0x00 0x00 0x04 0x78 0x00 0x00 0x00 0x03>;
				status = "disabled";
				phandle = <0x78>;
			};
		};

		iommu@594000000 {
			compatible = "apple,t6030-dart", "apple,t8110-dart";
			reg = <0x05 0x94000000 0x00 0x4000>;
			#iommu-cells = <0x01>;
			interrupt-parent = <0x13>;
			interrupts = <0x00 0x40f 0x04>;
			power-domains = <0x72>;
			phandle = <0x6e>;
		};

		iommu@595000000 {
			compatible = "apple,t6030-dart", "apple,t8110-dart";
			reg = <0x05 0x95000000 0x00 0x4000>;
			#iommu-cells = <0x01>;
			interrupt-parent = <0x13>;
			interrupts = <0x00 0x418 0x04>;
			power-domains = <0x72>;
			status = "okay";
			phandle = <0x6f>;
		};

		iommu@596000000 {
			compatible = "apple,t6030-dart", "apple,t8110-dart";
			reg = <0x05 0x96000000 0x00 0x4000>;
			#iommu-cells = <0x01>;
			interrupt-parent = <0x13>;
			interrupts = <0x00 0x421 0x04>;
			power-domains = <0x72>;
			status = "disabled";
			phandle = <0x70>;
		};

		iommu@597000000 {
			compatible = "apple,t6030-dart", "apple,t8110-dart";
			reg = <0x05 0x97000000 0x00 0x4000>;
			#iommu-cells = <0x01>;
			interrupt-parent = <0x13>;
			interrupts = <0x00 0x42a 0x04>;
			power-domains = <0x72>;
			status = "disabled";
			phandle = <0x71>;
		};
	};

	aliases {
		bluetooth0 = "/soc/pcie@580000000/pci@0,0/bluetooth@0,1";
		serial0 = "/soc/serial@2892000000";
		wifi0 = "/soc/pcie@580000000/pci@0,0/wifi@0,0";
		nvram = "/soc/spi@289104000/flash@0/partitions/partition@700000";
	};

	chosen {
		#address-cells = <0x02>;
		#size-cells = <0x02>;
		ranges;
		stdout-path = "serial0";

		framebuffer@0 {
			compatible = "apple,simple-framebuffer", "simple-framebuffer";
			reg = <0x00 0x00 0x00 0x00>;
			status = "disabled";
			power-domains = <0x79>;
		};
	};

	memory@10000000000 {
		device_type = "memory";
		reg = <0x100 0x00 0x02 0x00>;
	};

	led-controller {
		compatible = "pwm-leds";

		led-0 {
			pwms = <0x7a 0x00 0x9c40>;
			label = "kbd_backlight";
			function = "kbd_backlight";
			color = <0x00>;
			max-brightness = <0xff>;
			default-state = "keep";
		};
	};

	fixed-regulator-sn012776-sdz {
		compatible = "regulator-fixed";
		regulator-name = "sn012776-sdz";
		startup-delay-us = <0x1388>;
		gpios = <0x18 0x1c 0x00>;
		enable-active-high;
		phandle = <0x17>;
	};

	sound {
		compatible = "apple,j514-macaudio", "apple,j314-macaudio", "apple,macaudio";
		model = "MacBook Pro J514";

		dai-link@0 {
			link-name = "Speakers";

			cpu {
				sound-dai = <0x7b 0x00 0x7b 0x01>;
			};

			codec {
				sound-dai = <0x7c 0x7d 0x7e 0x7f 0x80 0x81>;
			};
		};

		dai-link@1 {
			link-name = "Headphone Jack";

			cpu {
				sound-dai = <0x7b 0x02>;
			};

			codec {
				sound-dai = <0x82>;
			};
		};
	};
};
